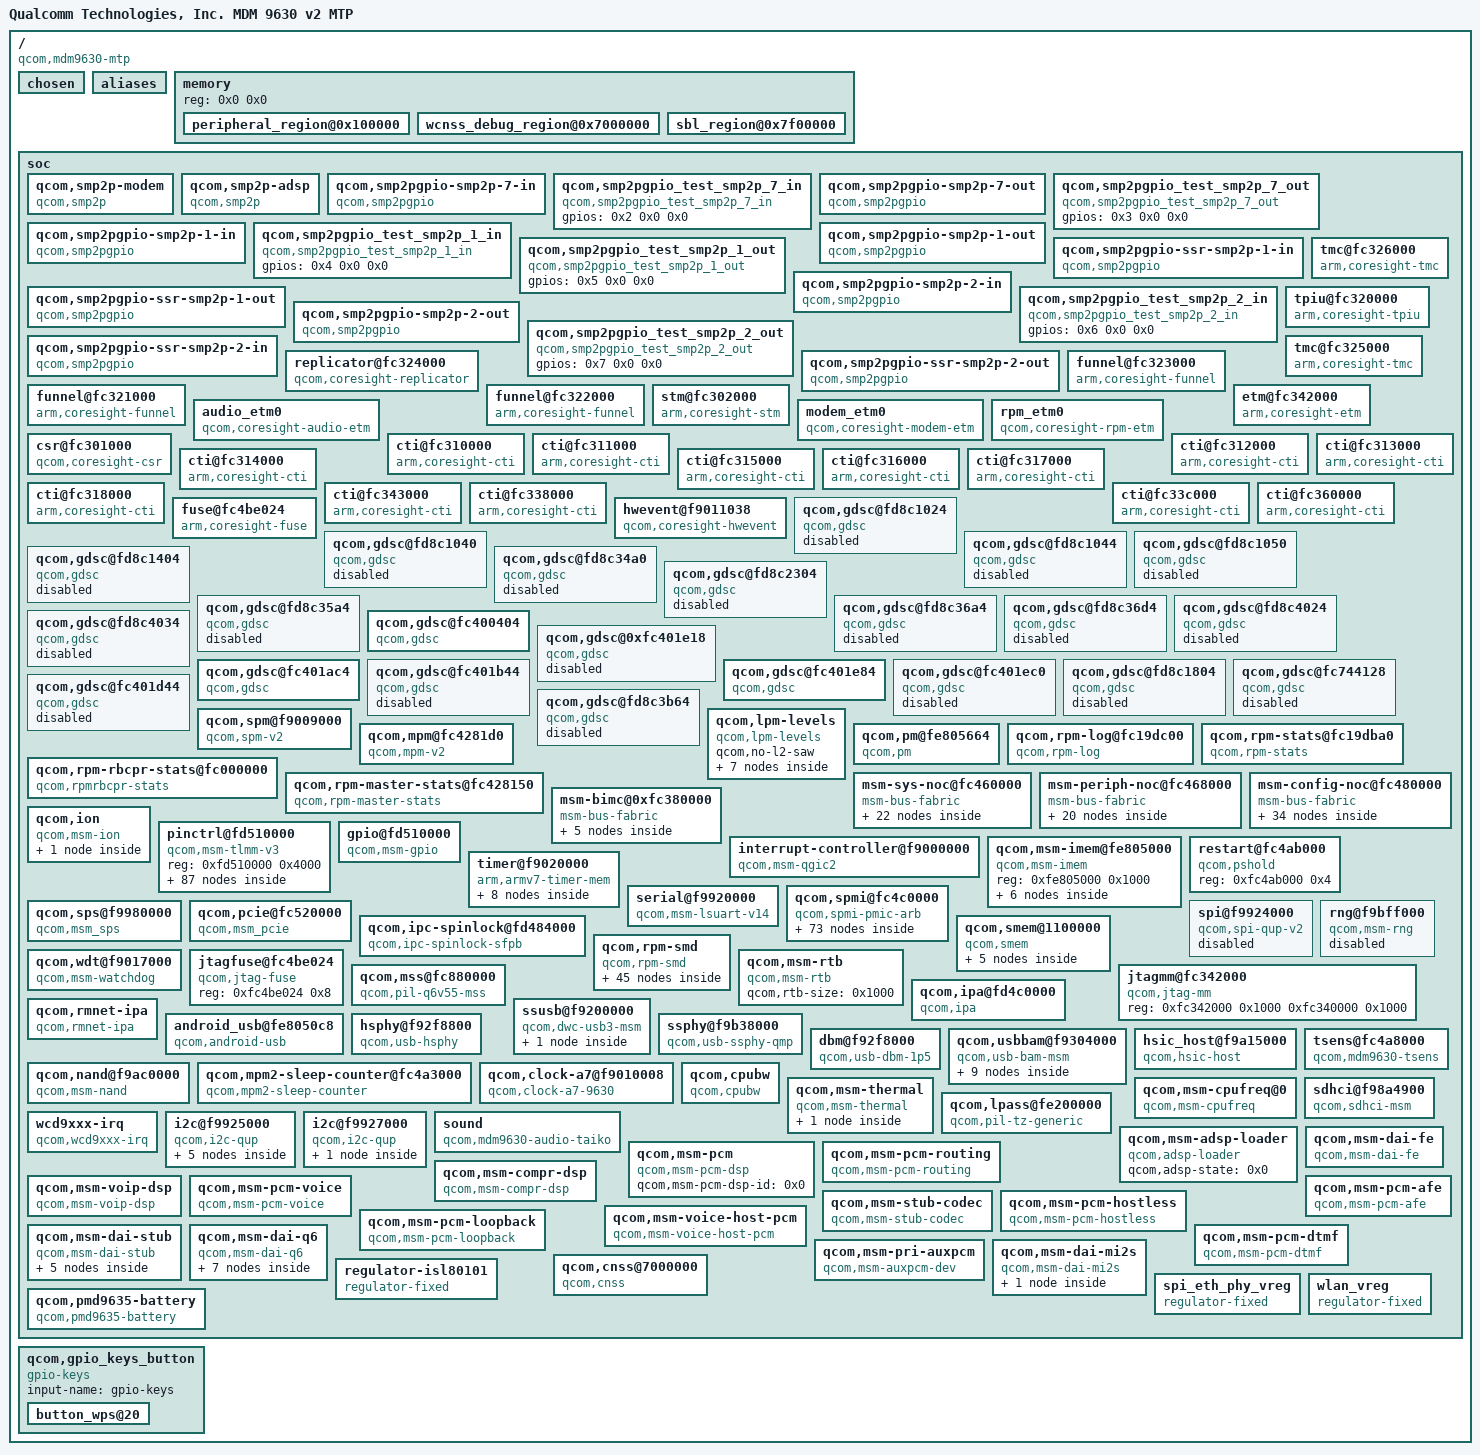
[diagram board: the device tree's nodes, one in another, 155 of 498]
/dts-v1/;

/memreserve/	0x0000000000000000 0x0000000000001000;
/ {
	#address-cells = <0x1>;
	#size-cells = <0x1>;
	model = "Qualcomm Technologies, Inc. MDM 9630 v2 MTP";
	compatible = "qcom,mdm9630-mtp", "qcom,mdm9630", "qcom,mtp";
	qcom,msm-id = <0x200bb 0x20000 0x200e3 0x20000 0x200e4 0x20000 0x200e5 0x20000 0x200e6 0x20000 0x200e7 0x20000>;
	interrupt-parent = <0x1>;
	qcom,board-id = <0x7 0x0>;

	chosen {
	};

	aliases {
		spi2 = "/soc/spi@f9924000";
		sdhc2 = "/soc/sdhci@f98a4900";
	};

	memory {
		#address-cells = <0x1>;
		#size-cells = <0x1>;
		device_type = "memory";
		reg = <0x0 0x0>;

		peripheral_region@0x100000 {
			linux,reserve-contiguous-region;
			linux,reserve-region;
			linux,remove-completely;
			reg = <0x1000000 0x5600000>;
			label = "peripheral_mem";
		};

		wcnss_debug_region@0x7000000 {
			linux,reserve-contiguous-region;
			linux,reserve-region;
			linux,remove-completely;
			reg = <0x7000000 0x100000>;
			label = "wcnss_debug_mem";
		};

		sbl_region@0x7f00000 {
			linux,reserve-contiguous-region;
			linux,reserve-region;
			linux,remove-completely;
			reg = <0x7f00000 0x100000>;
			label = "sbl_mem";
		};
	};

	soc {
		#address-cells = <0x1>;
		#size-cells = <0x1>;
		ranges;

		qcom,smp2p-modem {
			compatible = "qcom,smp2p";
			reg = <0xf9011008 0x4>;
			qcom,remote-pid = <0x1>;
			qcom,irq-bitmask = <0x4000>;
			interrupts = <0x0 0x1b 0x1>;
		};

		qcom,smp2p-adsp {
			compatible = "qcom,smp2p";
			reg = <0xf9011008 0x4>;
			qcom,remote-pid = <0x2>;
			qcom,irq-bitmask = <0x400>;
			interrupts = <0x0 0x9e 0x1>;
		};

		qcom,smp2pgpio-smp2p-7-in {
			compatible = "qcom,smp2pgpio";
			qcom,entry-name = "smp2p";
			qcom,remote-pid = <0x7>;
			qcom,is-inbound;
			gpio-controller;
			#gpio-cells = <0x2>;
			interrupt-controller;
			#interrupt-cells = <0x2>;
			linux,phandle = <0x2>;
			phandle = <0x2>;
		};

		qcom,smp2pgpio_test_smp2p_7_in {
			compatible = "qcom,smp2pgpio_test_smp2p_7_in";
			gpios = <0x2 0x0 0x0>;
		};

		qcom,smp2pgpio-smp2p-7-out {
			compatible = "qcom,smp2pgpio";
			qcom,entry-name = "smp2p";
			qcom,remote-pid = <0x7>;
			gpio-controller;
			#gpio-cells = <0x2>;
			interrupt-controller;
			#interrupt-cells = <0x2>;
			linux,phandle = <0x3>;
			phandle = <0x3>;
		};

		qcom,smp2pgpio_test_smp2p_7_out {
			compatible = "qcom,smp2pgpio_test_smp2p_7_out";
			gpios = <0x3 0x0 0x0>;
		};

		qcom,smp2pgpio-smp2p-1-in {
			compatible = "qcom,smp2pgpio";
			qcom,entry-name = "smp2p";
			qcom,remote-pid = <0x1>;
			qcom,is-inbound;
			gpio-controller;
			#gpio-cells = <0x2>;
			interrupt-controller;
			#interrupt-cells = <0x2>;
			linux,phandle = <0x4>;
			phandle = <0x4>;
		};

		qcom,smp2pgpio_test_smp2p_1_in {
			compatible = "qcom,smp2pgpio_test_smp2p_1_in";
			gpios = <0x4 0x0 0x0>;
		};

		qcom,smp2pgpio-smp2p-1-out {
			compatible = "qcom,smp2pgpio";
			qcom,entry-name = "smp2p";
			qcom,remote-pid = <0x1>;
			gpio-controller;
			#gpio-cells = <0x2>;
			interrupt-controller;
			#interrupt-cells = <0x2>;
			linux,phandle = <0x5>;
			phandle = <0x5>;
		};

		qcom,smp2pgpio_test_smp2p_1_out {
			compatible = "qcom,smp2pgpio_test_smp2p_1_out";
			gpios = <0x5 0x0 0x0>;
		};

		qcom,smp2pgpio-ssr-smp2p-1-in {
			compatible = "qcom,smp2pgpio";
			qcom,entry-name = "slave-kernel";
			qcom,remote-pid = <0x1>;
			qcom,is-inbound;
			gpio-controller;
			#gpio-cells = <0x2>;
			interrupt-controller;
			#interrupt-cells = <0x2>;
			linux,phandle = <0x1d>;
			phandle = <0x1d>;
		};

		qcom,smp2pgpio-ssr-smp2p-1-out {
			compatible = "qcom,smp2pgpio";
			qcom,entry-name = "master-kernel";
			qcom,remote-pid = <0x1>;
			gpio-controller;
			#gpio-cells = <0x2>;
			interrupt-controller;
			#interrupt-cells = <0x2>;
			linux,phandle = <0x1e>;
			phandle = <0x1e>;
		};

		qcom,smp2pgpio-smp2p-2-in {
			compatible = "qcom,smp2pgpio";
			qcom,entry-name = "smp2p";
			qcom,remote-pid = <0x2>;
			qcom,is-inbound;
			gpio-controller;
			#gpio-cells = <0x2>;
			interrupt-controller;
			#interrupt-cells = <0x2>;
			linux,phandle = <0x6>;
			phandle = <0x6>;
		};

		qcom,smp2pgpio_test_smp2p_2_in {
			compatible = "qcom,smp2pgpio_test_smp2p_2_in";
			gpios = <0x6 0x0 0x0>;
		};

		qcom,smp2pgpio-smp2p-2-out {
			compatible = "qcom,smp2pgpio";
			qcom,entry-name = "smp2p";
			qcom,remote-pid = <0x2>;
			gpio-controller;
			#gpio-cells = <0x2>;
			interrupt-controller;
			#interrupt-cells = <0x2>;
			linux,phandle = <0x7>;
			phandle = <0x7>;
		};

		qcom,smp2pgpio_test_smp2p_2_out {
			compatible = "qcom,smp2pgpio_test_smp2p_2_out";
			gpios = <0x7 0x0 0x0>;
		};

		qcom,smp2pgpio-ssr-smp2p-2-in {
			compatible = "qcom,smp2pgpio";
			qcom,entry-name = "slave-kernel";
			qcom,remote-pid = <0x2>;
			qcom,is-inbound;
			gpio-controller;
			#gpio-cells = <0x2>;
			interrupt-controller;
			#interrupt-cells = <0x2>;
			linux,phandle = <0x2a>;
			phandle = <0x2a>;
		};

		qcom,smp2pgpio-ssr-smp2p-2-out {
			compatible = "qcom,smp2pgpio";
			qcom,entry-name = "master-kernel";
			qcom,remote-pid = <0x2>;
			gpio-controller;
			#gpio-cells = <0x2>;
			interrupt-controller;
			#interrupt-cells = <0x2>;
			linux,phandle = <0x2b>;
			phandle = <0x2b>;
		};

		tmc@fc326000 {
			compatible = "arm,coresight-tmc";
			reg = <0xfc326000 0x1000 0xfc37c000 0x3000>;
			reg-names = "tmc-base", "bam-base";
			interrupts = <0x0 0xa6 0x0>;
			interrupt-names = "byte-cntr-irq";
			qcom,memory-size = <0x100000>;
			coresight-id = <0x0>;
			coresight-name = "coresight-tmc-etr";
			coresight-nr-inports = <0x1>;
			coresight-ctis = <0x8 0x9>;
			linux,phandle = <0xa>;
			phandle = <0xa>;
		};

		tpiu@fc320000 {
			compatible = "arm,coresight-tpiu";
			reg = <0xfc320000 0x1000>;
			reg-names = "tpiu-base";
			coresight-id = <0x1>;
			coresight-name = "coresight-tpiu";
			coresight-nr-inports = <0x1>;
			linux,phandle = <0xb>;
			phandle = <0xb>;
		};

		replicator@fc324000 {
			compatible = "qcom,coresight-replicator";
			reg = <0xfc324000 0x1000>;
			reg-names = "replicator-base";
			coresight-id = <0x2>;
			coresight-name = "coresight-replicator";
			coresight-nr-inports = <0x1>;
			coresight-outports = <0x0 0x1>;
			coresight-child-list = <0xa 0xb>;
			coresight-child-ports = <0x0 0x0>;
			linux,phandle = <0xc>;
			phandle = <0xc>;
		};

		tmc@fc325000 {
			compatible = "arm,coresight-tmc";
			reg = <0xfc325000 0x1000>;
			reg-names = "tmc-base";
			coresight-id = <0x3>;
			coresight-name = "coresight-tmc-etf";
			coresight-nr-inports = <0x1>;
			coresight-outports = <0x0>;
			coresight-child-list = <0xc>;
			coresight-child-ports = <0x0>;
			coresight-default-sink;
			coresight-ctis = <0x8 0x9>;
			linux,phandle = <0xd>;
			phandle = <0xd>;
		};

		funnel@fc323000 {
			compatible = "arm,coresight-funnel";
			reg = <0xfc323000 0x1000>;
			reg-names = "funnel-base";
			coresight-id = <0x4>;
			coresight-name = "coresight-funnel-merg";
			coresight-nr-inports = <0x2>;
			coresight-outports = <0x0>;
			coresight-child-list = <0xd>;
			coresight-child-ports = <0x0>;
			linux,phandle = <0xe>;
			phandle = <0xe>;
		};

		funnel@fc321000 {
			compatible = "arm,coresight-funnel";
			reg = <0xfc321000 0x1000>;
			reg-names = "funnel-base";
			coresight-id = <0x5>;
			coresight-name = "coresight-funnel-in0";
			coresight-nr-inports = <0x8>;
			coresight-outports = <0x0>;
			coresight-child-list = <0xe>;
			coresight-child-ports = <0x0>;
			linux,phandle = <0xf>;
			phandle = <0xf>;
		};

		funnel@fc322000 {
			compatible = "arm,coresight-funnel";
			reg = <0xfc322000 0x1000>;
			reg-names = "funnel-base";
			coresight-id = <0x6>;
			coresight-name = "coresight-funnel-in1";
			coresight-nr-inports = <0x8>;
			coresight-outports = <0x0>;
			coresight-child-list = <0xe>;
			coresight-child-ports = <0x1>;
			linux,phandle = <0x10>;
			phandle = <0x10>;
		};

		stm@fc302000 {
			compatible = "arm,coresight-stm";
			reg = <0xfc302000 0x1000 0xfa280000 0x180000>;
			reg-names = "stm-base", "stm-data-base";
			coresight-id = <0x7>;
			coresight-name = "coresight-stm";
			coresight-nr-inports = <0x0>;
			coresight-outports = <0x0>;
			coresight-child-list = <0xf>;
			coresight-child-ports = <0x7>;
		};

		etm@fc342000 {
			compatible = "arm,coresight-etm";
			reg = <0xfc342000 0x1000>;
			reg-names = "etm-base";
			coresight-id = <0x8>;
			coresight-name = "coresight-etm0";
			coresight-nr-inports = <0x0>;
			coresight-outports = <0x0>;
			coresight-child-list = <0x10>;
			coresight-child-ports = <0x2>;
			qcom,round-robin;
		};

		audio_etm0 {
			compatible = "qcom,coresight-audio-etm";
			coresight-id = <0x9>;
			coresight-name = "coresight-audio-etm0";
			coresight-nr-inports = <0x0>;
			coresight-outports = <0x0>;
			coresight-child-list = <0xf>;
			coresight-child-ports = <0x2>;
		};

		modem_etm0 {
			compatible = "qcom,coresight-modem-etm";
			coresight-id = <0xa>;
			coresight-name = "coresight-modem-etm0";
			coresight-nr-inports = <0x0>;
			coresight-outports = <0x0>;
			coresight-child-list = <0xf>;
			coresight-child-ports = <0x1>;
		};

		rpm_etm0 {
			compatible = "qcom,coresight-rpm-etm";
			coresight-id = <0xb>;
			coresight-name = "coresight-rpm-etm0";
			coresight-nr-inports = <0x0>;
			coresight-outports = <0x0>;
			coresight-child-list = <0xf>;
			coresight-child-ports = <0x0>;
		};

		csr@fc301000 {
			compatible = "qcom,coresight-csr";
			reg = <0xfc301000 0x1000>;
			reg-names = "csr-base";
			coresight-id = <0xc>;
			coresight-name = "coresight-csr";
			coresight-nr-inports = <0x0>;
			qcom,blk-size = <0x1>;
		};

		cti@fc310000 {
			compatible = "arm,coresight-cti";
			reg = <0xfc310000 0x1000>;
			reg-names = "cti-base";
			coresight-id = <0xd>;
			coresight-name = "coresight-cti0";
			coresight-nr-inports = <0x0>;
			linux,phandle = <0x8>;
			phandle = <0x8>;
		};

		cti@fc311000 {
			compatible = "arm,coresight-cti";
			reg = <0xfc311000 0x1000>;
			reg-names = "cti-base";
			coresight-id = <0xe>;
			coresight-name = "coresight-cti1";
			coresight-nr-inports = <0x0>;
		};

		cti@fc312000 {
			compatible = "arm,coresight-cti";
			reg = <0xfc312000 0x1000>;
			reg-names = "cti-base";
			coresight-id = <0xf>;
			coresight-name = "coresight-cti2";
			coresight-nr-inports = <0x0>;
		};

		cti@fc313000 {
			compatible = "arm,coresight-cti";
			reg = <0xfc313000 0x1000>;
			reg-names = "cti-base";
			coresight-id = <0x10>;
			coresight-name = "coresight-cti3";
			coresight-nr-inports = <0x0>;
		};

		cti@fc314000 {
			compatible = "arm,coresight-cti";
			reg = <0xfc314000 0x1000>;
			reg-names = "cti-base";
			coresight-id = <0x11>;
			coresight-name = "coresight-cti4";
			coresight-nr-inports = <0x0>;
		};

		cti@fc315000 {
			compatible = "arm,coresight-cti";
			reg = <0xfc315000 0x1000>;
			reg-names = "cti-base";
			coresight-id = <0x12>;
			coresight-name = "coresight-cti5";
			coresight-nr-inports = <0x0>;
		};

		cti@fc316000 {
			compatible = "arm,coresight-cti";
			reg = <0xfc316000 0x1000>;
			reg-names = "cti-base";
			coresight-id = <0x13>;
			coresight-name = "coresight-cti6";
			coresight-nr-inports = <0x0>;
		};

		cti@fc317000 {
			compatible = "arm,coresight-cti";
			reg = <0xfc317000 0x1000>;
			reg-names = "cti-base";
			coresight-id = <0x14>;
			coresight-name = "coresight-cti7";
			coresight-nr-inports = <0x0>;
		};

		cti@fc318000 {
			compatible = "arm,coresight-cti";
			reg = <0xfc318000 0x1000>;
			reg-names = "cti-base";
			coresight-id = <0x15>;
			coresight-name = "coresight-cti8";
			coresight-nr-inports = <0x0>;
			linux,phandle = <0x9>;
			phandle = <0x9>;
		};

		cti@fc343000 {
			compatible = "arm,coresight-cti";
			reg = <0xfc343000 0x1000>;
			reg-names = "cti-base";
			coresight-id = <0x16>;
			coresight-name = "coresight-cti-cpu0";
			coresight-nr-inports = <0x0>;
		};

		cti@fc338000 {
			compatible = "arm,coresight-cti";
			reg = <0xfc338000 0x1000>;
			reg-names = "cti-base";
			coresight-id = <0x17>;
			coresight-name = "coresight-cti-modem-cpu0";
			coresight-nr-inports = <0x0>;
		};

		cti@fc33c000 {
			compatible = "arm,coresight-cti";
			reg = <0xfc33c000 0x1000>;
			reg-names = "cti-base";
			coresight-id = <0x18>;
			coresight-name = "coresight-cti-audio-cpu0";
			coresight-nr-inports = <0x0>;
		};

		cti@fc360000 {
			compatible = "arm,coresight-cti";
			reg = <0xfc360000 0x1000>;
			reg-names = "cti-base";
			coresight-id = <0x19>;
			coresight-name = "coresight-cti-rpm-cpu0";
			coresight-nr-inports = <0x0>;
		};

		hwevent@f9011038 {
			compatible = "qcom,coresight-hwevent";
			reg = <0xf9011038 0x80 0xfd4ab160 0x80 0xfc401600 0x80>;
			reg-names = "apcs-mux", "ppss-mux", "gcc-mux";
			coresight-id = <0x1a>;
			coresight-name = "coresight-hwevent";
			coresight-nr-inports = <0x0>;
		};

		fuse@fc4be024 {
			compatible = "arm,coresight-fuse";
			reg = <0xfc4be024 0x8>;
			reg-names = "fuse-base";
			coresight-id = <0x1b>;
			coresight-name = "coresight-fuse";
			coresight-nr-inports = <0x0>;
		};

		qcom,gdsc@fd8c1024 {
			compatible = "qcom,gdsc";
			regulator-name = "gdsc_venus";
			reg = <0xfd8c1024 0x4>;
			status = "disabled";
		};

		qcom,gdsc@fd8c1040 {
			compatible = "qcom,gdsc";
			regulator-name = "gdsc_venus_core0";
			reg = <0xfd8c1040 0x4>;
			status = "disabled";
		};

		qcom,gdsc@fd8c1044 {
			compatible = "qcom,gdsc";
			regulator-name = "gdsc_venus_core1";
			reg = <0xfd8c1044 0x4>;
			status = "disabled";
		};

		qcom,gdsc@fd8c1050 {
			compatible = "qcom,gdsc";
			regulator-name = "gdsc_venus_core2";
			reg = <0xfd8c1050 0x4>;
			status = "disabled";
		};

		qcom,gdsc@fd8c1404 {
			compatible = "qcom,gdsc";
			regulator-name = "gdsc_vpu";
			reg = <0xfd8c1404 0x4>;
			status = "disabled";
		};

		qcom,gdsc@fd8c34a0 {
			compatible = "qcom,gdsc";
			regulator-name = "gdsc_camss_top";
			reg = <0xfd8c34a0 0x4>;
			status = "disabled";
		};

		qcom,gdsc@fd8c2304 {
			compatible = "qcom,gdsc";
			regulator-name = "gdsc_mdss";
			reg = <0xfd8c2304 0x4>;
			status = "disabled";
		};

		qcom,gdsc@fd8c35a4 {
			compatible = "qcom,gdsc";
			regulator-name = "gdsc_jpeg";
			reg = <0xfd8c35a4 0x4>;
			status = "disabled";
		};

		qcom,gdsc@fd8c36a4 {
			compatible = "qcom,gdsc";
			regulator-name = "gdsc_vfe";
			reg = <0xfd8c36a4 0x4>;
			status = "disabled";
		};

		qcom,gdsc@fd8c36d4 {
			compatible = "qcom,gdsc";
			regulator-name = "gdsc_cpp";
			reg = <0xfd8c36d4 0x4>;
			status = "disabled";
		};

		qcom,gdsc@fd8c4024 {
			compatible = "qcom,gdsc";
			regulator-name = "gdsc_oxili_gx";
			reg = <0xfd8c4024 0x4>;
			status = "disabled";
		};

		qcom,gdsc@fd8c4034 {
			compatible = "qcom,gdsc";
			regulator-name = "gdsc_oxili_cx";
			reg = <0xfd8c4034 0x4>;
			status = "disabled";
		};

		qcom,gdsc@fc400404 {
			compatible = "qcom,gdsc";
			regulator-name = "gdsc_usb_hsic";
			reg = <0xfc400404 0x4>;
			status = "ok";
			linux,phandle = <0x28>;
			phandle = <0x28>;
		};

		qcom,gdsc@0xfc401e18 {
			compatible = "qcom,gdsc";
			regulator-name = "gdsc_pcie";
			reg = <0xfc401e18 0x4>;
			status = "disabled";
		};

		qcom,gdsc@fc401ac4 {
			compatible = "qcom,gdsc";
			regulator-name = "gdsc_pcie_0";
			reg = <0xfc401e18 0x4>;
			status = "ok";
			linux,phandle = <0x16>;
			phandle = <0x16>;
		};

		qcom,gdsc@fc401b44 {
			compatible = "qcom,gdsc";
			regulator-name = "gdsc_pcie_1";
			reg = <0xfc401b44 0x4>;
			status = "disabled";
		};

		qcom,gdsc@fc401e84 {
			compatible = "qcom,gdsc";
			regulator-name = "gdsc_usb30";
			reg = <0xfc401b80 0x4>;
			status = "ok";
			linux,phandle = <0x21>;
			phandle = <0x21>;
		};

		qcom,gdsc@fc401ec0 {
			compatible = "qcom,gdsc";
			regulator-name = "gdsc_usb30_sec";
			reg = <0xfc401ec0 0x4>;
			status = "disabled";
		};

		qcom,gdsc@fd8c1804 {
			compatible = "qcom,gdsc";
			regulator-name = "gdsc_vcap";
			reg = <0xfd8c1804 0x4>;
			status = "disabled";
		};

		qcom,gdsc@fc744128 {
			compatible = "qcom,gdsc";
			regulator-name = "gdsc_bcss";
			reg = <0xfc744128 0x4>;
			status = "disabled";
		};

		qcom,gdsc@fc401d44 {
			compatible = "qcom,gdsc";
			regulator-name = "gdsc_ufs";
			reg = <0xfc401d44 0x4>;
			status = "disabled";
		};

		qcom,gdsc@fd8c3b64 {
			compatible = "qcom,gdsc";
			regulator-name = "gdsc_fd";
			reg = <0xfd8c3b64 0x4>;
			status = "disabled";
		};

		qcom,spm@f9009000 {
			compatible = "qcom,spm-v2";
			#address-cells = <0x1>;
			#size-cells = <0x1>;
			reg = <0xf9009000 0x1000>;
			qcom,core-id = <0x0>;
			qcom,saw2-ver-reg = <0xfd0>;
			qcom,saw2-cfg = <0x101>;
			#qcom,saw2-spm-dly = <0x0>;
			qcom,saw2-spm-dly = <0x3c102800>;
			qcom,saw2-spm-ctl = <0x1>;
			qcom,saw2-spm-cmd-wfi = <0x403040f>;
			qcom,saw2-spm-cmd-spc = <0x34044424 0x54035a24 0x44043a0f>;
			qcom,saw2-spm-cmd-pc = <0x34041424 0x54075a24 0x14043e0f>;
		};

		qcom,lpm-levels {
			compatible = "qcom,lpm-levels";
			qcom,no-l2-saw;
			#address-cells = <0x1>;
			#size-cells = <0x0>;

			qcom,cpu-modes {
				compatible = "qcom,cpu-modes";

				qcom,cpu-mode@0 {
					qcom,mode = "wfi";
					qcom,latency-us = <0x64>;
					qcom,ss-power = <0x1f40>;
					qcom,energy-overhead = <0x186a0>;
					qcom,time-overhead = <0x1>;
				};

				qcom,cpu-mode@1 {
					qcom,mode = "standalone_pc";
					qcom,latency-us = <0x7d0>;
					qcom,ss-power = <0x1388>;
					qcom,energy-overhead = <0x3950da0>;
					qcom,time-overhead = <0xbb8>;
				};

				qcom,cpu-mode@2 {
					qcom,mode = "pc";
					qcom,latency-us = <0x7530>;
					qcom,ss-power = <0x1388>;
					qcom,energy-overhead = <0x398de30>;
					qcom,time-overhead = <0x1c84>;
				};
			};

			qcom,system-modes {
				compatible = "qcom,system-modes";

				qcom,system-mode@0 {
					qcom,l2 = "l2_cache_pc";
					qcom,latency-us = <0x7d0>;
					qcom,ss-power = <0x1388>;
					qcom,energy-overhead = <0x3950da0>;
					qcom,time-overhead = <0xbb8>;
					qcom,min-cpu-mode = "standalone_pc";
					qcom,sync-mode;
				};

				qcom,system-mode@1 {
					qcom,l2 = "l2_cache_pc";
					qcom,latency-us = <0x7530>;
					qcom,ss-power = <0x1388>;
					qcom,energy-overhead = <0x398de30>;
					qcom,time-overhead = <0x1c84>;
					qcom,min-cpu-mode = "pc";
					qcom,send-rpm-sleep-set;
					qcom,sync-mode;
				};
			};
		};

		qcom,mpm@fc4281d0 {
			compatible = "qcom,mpm-v2";
			reg = <0xfc4281d0 0x1000 0xf9011008 0x4>;
			reg-names = "vmpm", "ipc";
			interrupts = <0x0 0xab 0x1>;
			clock-names = "xo";
			qcom,ipc-bit-offset = <0x1>;
			qcom,gic-parent = <0x1>;
			qcom,gic-map = <0x2 0xd8 0x2f 0xac 0x29 0xb4 0x3e 0xde 0xff 0x12 0xff 0x26 0xff 0x38 0xff 0x39 0xff 0x3a 0xff 0x3b 0xff 0x3c 0xff 0x49 0xff 0x7e 0x31 0xa5 0x36 0xd4 0xff 0xad 0xff 0xae 0xff 0xaf 0xff 0xb0 0xff 0xb1 0xff 0xb2 0xff 0xb3 0xff 0xbc 0xff 0xbd 0xff 0xbe 0xff 0xbf 0xff 0xc0 0xff 0xc1 0xff 0xc2 0xff 0xc3 0xff 0xc4 0xff 0xc5 0xff 0xc6 0xff 0xc8 0xff 0xc9 0xff 0xca 0xff 0xcb 0xff 0xcc 0xff 0xcd 0xff 0xce 0xff 0xcf 0xff 0xf0 0xff 0x10e>;
			qcom,gpio-parent = <0x11>;
			qcom,gpio-map = <0x3 0x50 0x4 0x0 0x5 0x1 0x6 0x2 0x7 0x3 0x8 0x4 0x9 0x5 0xa 0x6 0xb 0x7 0xc 0x8 0xd 0x9 0xe 0xa 0xf 0xb 0x10 0xc 0x11 0xd 0x12 0xe 0x13 0xf 0x14 0x10 0x15 0x11 0x16 0x12 0x17 0x13 0x18 0x14 0x19 0x15 0x1a 0x18 0x1b 0x19 0x1c 0x33 0x1d 0x51 0x1e 0x3e 0x1f 0x3f 0x20 0x40 0x21 0x41 0x22 0x42 0x23 0x43 0x24 0x2b 0x25 0x32 0x26 0x35 0x27 0x36 0x28 0x37 0x2a 0x38 0x2b 0x52 0x2f 0x4d 0x32 0x53 0x33 0x54 0x34 0x55 0x35 0x3a 0x37 0x3b 0x39 0x44 0x3b 0x46>;
		};

		qcom,pm@fe805664 {
			compatible = "qcom,pm";
			reg = <0xfe805664 0x40>;
			qcom,use-sync-timer;
			qcom,synced-clocks;
		};

		qcom,rpm-log@fc19dc00 {
			compatible = "qcom,rpm-log";
			reg = <0xfc19dc00 0x4000>;
			qcom,rpm-addr-phys = <0xfc000000>;
			qcom,offset-version = <0x4>;
			qcom,offset-page-buffer-addr = <0x24>;
			qcom,offset-log-len = <0x28>;
			qcom,offset-log-len-mask = <0x2c>;
			qcom,offset-page-indices = <0x38>;
		};

		qcom,rpm-stats@fc19dba0 {
			compatible = "qcom,rpm-stats";
			reg = <0xfc19dba0 0x1000>;
			reg-names = "phys_addr_base";
			qcom,sleep-stats-version = <0x2>;
		};

		qcom,rpm-rbcpr-stats@fc000000 {
			compatible = "qcom,rpmrbcpr-stats";
			reg = <0xfc000000 0x1a0000>;
			qcom,start-offset = <0x190010>;
		};

		qcom,rpm-master-stats@fc428150 {
			compatible = "qcom,rpm-master-stats";
			reg = <0xfc428150 0x3200>;
			qcom,masters = "APSS", "MPSS", "LPSS";
			qcom,master-stats-version = <0x2>;
			qcom,master-offset = <0xa00>;
		};

		msm-sys-noc@fc460000 {
			compatible = "msm-bus-fabric";
			reg = <0xfc460000 0x4000>;
			cell-id = <0x400>;
			label = "msm_sys_noc";
			qcom,fabclk-dual = "bus_clk";
			qcom,fabclk-active = "bus_a_clk";
			qcom,ntieredslaves = <0x0>;
			qcom,qos-freq = <0x12c0>;
			qcom,hw-sel = "NoC";
			qcom,rpm-en;
			qcom,nfab = <0x4>;

			mas-lpass-ahb {
				cell-id = <0x34>;
				label = "mas-lpass-ahb";
				qcom,masterp = <0x0>;
				qcom,tier = <0x2>;
				qcom,qport = <0x0>;
				qcom,mas-hw-id = <0x12>;
				qcom,mode = "Fixed";
				qcom,prio-rd = <0x2>;
				qcom,prio-wr = <0x2>;
			};

			mas-qdss-bam {
				cell-id = <0x35>;
				label = "mas-qdss-bam";
				qcom,masterp = <0x1>;
				qcom,tier = <0x2>;
				qcom,mode = "Fixed";
				qcom,qport = <0x1>;
				qcom,mas-hw-id = <0x13>;
			};

			mas-snoc-cfg {
				cell-id = <0x36>;
				label = "mas-snoc-cfg";
				qcom,masterp = <0x2>;
				qcom,tier = <0x2>;
				qcom,mas-hw-id = <0x14>;
			};

			fab-bimc {
				cell-id = <0x0>;
				label = "fab-bimc";
				qcom,gateway;
				qcom,slavep = <0x2>;
				qcom,masterp = <0x3>;
				qcom,buswidth = <0x8>;
				qcom,mas-hw-id = <0x15>;
				qcom,slv-hw-id = <0x18>;
			};

			fab-cnoc {
				cell-id = <0x1400>;
				label = "fab-cnoc";
				qcom,gateway;
				qcom,slavep = <0x3>;
				qcom,masterp = <0x4>;
				qcom,buswidth = <0x8>;
				qcom,mas-hw-id = <0x16>;
				qcom,slv-hw-id = <0x19>;
			};

			fab-pnoc {
				cell-id = <0x1000>;
				label = "fab-pnoc";
				qcom,gateway;
				qcom,slavep = <0x5>;
				qcom,masterp = <0xb>;
				qcom,buswidth = <0x8>;
				qcom,qport = <0x8>;
				qcom,mas-hw-id = <0x1d>;
				qcom,slv-hw-id = <0x1c>;
				qcom,mode = "Fixed";
				qcom,prio-rd = <0x2>;
				qcom,prio-wr = <0x2>;
			};

			fab-ovnoc {
				cell-id = <0x1800>;
				label = "fab-ovnoc";
				qcom,gateway;
				qcom,buswidth = <0x8>;
				qcom,mas-hw-id = <0x35>;
				qcom,slv-hw-id = <0x4d>;
			};

			mas-crypto-core0 {
				cell-id = <0x37>;
				label = "mas-crypto-core0";
				qcom,masterp = <0x5>;
				qcom,tier = <0x2>;
				qcom,mode = "Fixed";
				qcom,qport = <0x2>;
				qcom,mas-hw-id = <0x17>;
				qcom,hw-sel = "NoC";
			};

			mas-lpass-proc {
				cell-id = <0xb>;
				label = "mas-lpass-proc";
				qcom,masterp = <0x7>;
				qcom,tier = <0x2>;
				qcom,qport = <0x4>;
				qcom,mas-hw-id = <0x19>;
				qcom,mode = "Fixed";
				qcom,prio-rd = <0x2>;
				qcom,prio-wr = <0x2>;
			};

			mas-mss {
				cell-id = <0x26>;
				label = "mas-mss";
				qcom,masterp = <0x8>;
				qcom,tier = <0x2>;
				qcom,mas-hw-id = <0x1a>;
			};

			mas-mss-nav {
				cell-id = <0x39>;
				label = "mas-mss-nav";
				qcom,masterp = <0x9>;
				qcom,tier = <0x2>;
				qcom,mas-hw-id = <0x1b>;
			};

			mas-ipa {
				cell-id = <0x5a>;
				label = "mas-ipa";
				qcom,masterp = <0x6>;
				qcom,tier = <0x2>;
				qcom,mode = "Fixed";
				qcom,qport = <0x3>;
				qcom,mas-hw-id = <0x3b>;
				qcom,hw-sel = "NoC";
				qcom,iface-clk-node = "msm_ipa";
			};

			mas-qdss-etr {
				cell-id = <0x3c>;
				label = "mas-qdss-etr";
				qcom,masterp = <0xc>;
				qcom,tier = <0x2>;
				qcom,qport = <0xa>;
				qcom,mode = "Fixed";
				qcom,mas-hw-id = <0x1f>;
			};

			mas-usb3 {
				cell-id = <0x3d>;
				label = "mas-usb3";
				qcom,masterp = <0xa>;
				qcom,tier = <0x2>;
				qcom,qport = <0x7>;
				qcom,mode = "Fixed";
				qcom,mas-hw-id = <0x20>;
				qcom,hw-sel = "NoC";
				qcom,iface-clk-node = "msm_usb3";
			};

			mas-pcie-0 {
				cell-id = <0x2d>;
				label = "mas-pcie-0";
				qcom,masterp = <0xd>;
				qcom,tier = <0x2>;
				qcom,mode = "Fixed";
				qcom,mas-hw-id = <0x41>;
				qcom,hw-sel = "NoC";
			};

			slv-ampss {
				cell-id = <0x208>;
				label = "slv-ampss";
				qcom,slavep = <0x0>;
				qcom,tier = <0x2>;
				qcom,buswidth = <0x8>;
				qcom,slv-hw-id = <0x14>;
			};

			slv-lpass {
				cell-id = <0x20a>;
				label = "slv-lpass";
				qcom,slavep = <0x1>;
				qcom,tier = <0x2>;
				qcom,buswidth = <0x8>;
				qcom,slv-hw-id = <0x15>;
			};

			slv-ocimem {
				cell-id = <0x249>;
				label = "slv-ocimem";
				qcom,slavep = <0x4>;
				qcom,tier = <0x2>;
				qcom,buswidth = <0x8>;
				qcom,slv-hw-id = <0x1a>;
			};

			slv-service-snoc {
				cell-id = <0x24b>;
				label = "slv-service-snoc";
				qcom,slavep = <0x6>;
				qcom,tier = <0x2>;
				qcom,buswidth = <0x8>;
				qcom,slv-hw-id = <0x1d>;
			};

			slv-qdss-stm {
				cell-id = <0x24c>;
				label = "slv-qdss-stm";
				qcom,slavep = <0x7>;
				qcom,tier = <0x2>;
				qcom,buswidth = <0x8>;
				qcom,slv-hw-id = <0x1e>;
			};

			slv-usb3 {
				cell-id = <0x247>;
				label = "slv-usb3";
				qcom,slavep = <0x9>;
				qcom,tier = <0x2>;
				qcom,buswidth = <0x8>;
				qcom,slv-hw-id = <0x16>;
			};

			slv-pcie-0 {
				cell-id = <0x28d>;
				label = "slv-pcie-0";
				qcom,slavep = <0x8>;
				qcom,tier = <0x2>;
				qcom,buswidth = <0x8>;
				qcom,slv-hw-id = <0x55>;
			};
		};

		msm-periph-noc@fc468000 {
			compatible = "msm-bus-fabric";
			reg = <0xfc468000 0x4000>;
			cell-id = <0x1000>;
			label = "msm_periph_noc";
			qcom,fabclk-dual = "bus_clk";
			qcom,fabclk-active = "bus_a_clk";
			qcom,ntieredslaves = <0x0>;
			qcom,hw-sel = "NoC";
			qcom,nfab = <0x4>;
			qcom,rpm-en;

			mas-pnoc-cfg {
				cell-id = <0x58>;
				label = "mas-pnoc-cfg";
				qcom,masterp = <0x7>;
				qcom,tier = <0x2>;
				qcom,buswidth = <0x8>;
				qcom,mas-hw-id = <0x2b>;
			};

			mas-qpic-cfg {
				cell-id = <0x5b>;
				label = "mas-qpic";
				qcom,masterp = <0x1>;
				qcom,tier = <0x2>;
				qcom,buswidth = <0x8>;
				qcom,mas-hw-id = <0x3a>;
			};

			mas-sdcc-2 {
				cell-id = <0x51>;
				label = "mas-sdcc-2";
				qcom,masterp = <0x2>;
				qcom,tier = <0x2>;
				qcom,buswidth = <0x8>;
				qcom,mas-hw-id = <0x23>;
			};

			mas-bam-dma {
				cell-id = <0x53>;
				label = "mas-bam-dma";
				qcom,masterp = <0x3>;
				qcom,tier = <0x2>;
				qcom,buswidth = <0x8>;
				qcom,mas-hw-id = <0x26>;
			};

			mas-usb-hsic {
				cell-id = <0x55>;
				label = "mas-usb-hsic";
				qcom,masterp = <0x4>;
				qcom,tier = <0x2>;
				qcom,buswidth = <0x8>;
				qcom,mas-hw-id = <0x28>;
			};

			mas-blsp-1 {
				cell-id = <0x56>;
				label = "mas-blsp-1";
				qcom,masterp = <0x5>;
				qcom,tier = <0x2>;
				qcom,buswidth = <0x8>;
				qcom,mas-hw-id = <0x29>;
			};

			mas-usb-hs {
				cell-id = <0x57>;
				label = "mas-usb-hs";
				qcom,masterp = <0x6>;
				qcom,tier = <0x2>;
				qcom,buswidth = <0x8>;
				qcom,mas-hw-id = <0x2a>;
			};

			fab-snoc {
				cell-id = <0x400>;
				label = "fab-snoc";
				qcom,gateway;
				qcom,slavep = <0xc>;
				qcom,masterp = <0x8>;
				qcom,tier = <0x2>;
				qcom,buswidth = <0x8>;
				qcom,slv-hw-id = <0x2d>;
				qcom,mas-hw-id = <0x2c>;
			};

			slv-qpic {
				cell-id = <0x288>;
				label = "slv-qpic";
				qcom,slavep = <0x2>;
				qcom,tier = <0x2>;
				qcom,buswidth = <0x8>;
				qcom,slv-hw-id = <0x51>;
			};

			slv-sdcc-2 {
				cell-id = <0x260>;
				label = "slv-sdcc-2";
				qcom,slavep = <0x1>;
				qcom,tier = <0x2>;
				qcom,buswidth = <0x8>;
				qcom,slv-hw-id = <0x21>;
			};

			slv-bam-dma {
				cell-id = <0x262>;
				label = "slv-bam-dma";
				qcom,slavep = <0x2>;
				qcom,tier = <0x2>;
				qcom,buswidth = <0x8>;
				qcom,slv-hw-id = <0x24>;
			};

			slv-usb-hsic {
				cell-id = <0x264>;
				label = "slv-usb-hsic";
				qcom,slavep = <0x3>;
				qcom,tier = <0x2>;
				qcom,buswidth = <0x8>;
				qcom,slv-hw-id = <0x26>;
			};

			slv-blsp-1 {
				cell-id = <0x265>;
				label = "slv-blsp-1";
				qcom,slavep = <0x5>;
				qcom,tier = <0x2>;
				qcom,buswidth = <0x8>;
				qcom,slv-hw-id = <0x27>;
			};

			slv-usb-hs {
				cell-id = <0x266>;
				label = "slv-usb-hs";
				qcom,slavep = <0x5>;
				qcom,tier = <0x2>;
				qcom,buswidth = <0x8>;
				qcom,slv-hw-id = <0x28>;
			};

			slv-pdm {
				cell-id = <0x267>;
				label = "slv-pdm";
				qcom,slavep = <0x6>;
				qcom,tier = <0x2>;
				qcom,buswidth = <0x8>;
				qcom,slv-hw-id = <0x29>;
			};

			slv-periph-apu-cfg {
				cell-id = <0x268>;
				label = "slv-periph-apu-cfg";
				qcom,slavep = <0x7>;
				qcom,tier = <0x2>;
				qcom,buswidth = <0x8>;
				qcom,slv-hw-id = <0x2a>;
			};

			slv-pnoc-mpu-cfg {
				cell-id = <0x269>;
				label = "slv-pnoc-mpu-cfg";
				qcom,slavep = <0x8>;
				qcom,tier = <0x2>;
				qcom,buswidth = <0x8>;
				qcom,slv-hw-id = <0x2b>;
			};

			slv-usb-phy {
				cell-id = <0x28d>;
				label = "slv-usb-phy";
				qcom,slavep = <0x9>;
				qcom,tier = <0x2>;
				qcom,buswidth = <0x8>;
				qcom,slv-hw-id = <0x5f>;
			};

			slv-prng {
				cell-id = <0x26a>;
				label = "slv-prng";
				qcom,slavep = <0xa>;
				qcom,tier = <0x2>;
				qcom,buswidth = <0x8>;
				qcom,slv-hw-id = <0x2c>;
			};

			slv-service-pnoc {
				cell-id = <0x26b>;
				label = "slv-service-pnoc";
				qcom,slavep = <0xc>;
				qcom,tier = <0x2>;
				qcom,buswidth = <0x8>;
				qcom,slv-hw-id = <0x2e>;
			};
		};

		msm-config-noc@fc480000 {
			compatible = "msm-bus-fabric";
			reg = <0xfc480000 0x4000>;
			cell-id = <0x1400>;
			label = "msm_config_noc";
			qcom,fabclk-dual = "bus_clk";
			qcom,fabclk-active = "bus_a_clk";
			qcom,ntieredslaves = <0x0>;
			qcom,hw-sel = "NoC";
			qcom,nfab = <0x4>;
			qcom,rpm-en;

			mas-rpm-inst {
				cell-id = <0x48>;
				label = "mas-rpm-inst";
				qcom,masterp = <0x0>;
				qcom,tier = <0x2>;
				qcom,buswidth = <0x8>;
				qcom,mas-hw-id = <0x2d>;
			};

			mas-rpm-data {
				cell-id = <0x49>;
				label = "mas-rpm-data";
				qcom,masterp = <0x1>;
				qcom,tier = <0x2>;
				qcom,buswidth = <0x8>;
				qcom,mas-hw-id = <0x2e>;
			};

			mas-rpm-sys {
				cell-id = <0x4a>;
				label = "mas-rpm-sys";
				qcom,masterp = <0x2>;
				qcom,tier = <0x2>;
				qcom,buswidth = <0x8>;
				qcom,mas-hw-id = <0x2f>;
			};

			mas-dehr {
				cell-id = <0x4b>;
				label = "mas-dehr";
				qcom,masterp = <0x3>;
				qcom,tier = <0x2>;
				qcom,buswidth = <0x8>;
				qcom,mas-hw-id = <0x30>;
			};

			mas-qdss-dap {
				cell-id = <0x4c>;
				label = "mas-qdss-dap";
				qcom,masterp = <0x4>;
				qcom,tier = <0x2>;
				qcom,buswidth = <0x8>;
				qcom,mas-hw-id = <0x31>;
			};

			mas-spdm {
				cell-id = <0x24>;
				label = "mas-spdm";
				qcom,masterp = <0x5>;
				qcom,tier = <0x2>;
				qcom,buswidth = <0x8>;
				qcom,mas-hw-id = <0x32>;
			};

			mas-tic {
				cell-id = <0x4d>;
				label = "mas-tic";
				qcom,masterp = <0x6>;
				qcom,tier = <0x2>;
				qcom,buswidth = <0x8>;
				qcom,mas-hw-id = <0x33>;
			};

			fab-snoc {
				cell-id = <0x400>;
				label = "fab-snoc";
				qcom,gateway;
				qcom,slavep = <0x1a>;
				qcom,masterp = <0x7>;
				qcom,tier = <0x2>;
				qcom,buswidth = <0x8>;
				qcom,mas-hw-id = <0x34>;
				qcom,slv-hw-id = <0x4b>;
			};

			slv-clk-ctl {
				cell-id = <0x26c>;
				label = "slv-clk-ctl";
				qcom,slavep = <0x0>;
				qcom,tier = <0x2>;
				qcom,buswidth = <0x8>;
				qcom,slv-hw-id = <0x2f>;
			};

			slv-cnoc-mss {
				cell-id = <0x26d>;
				label = "slv-cnoc-mss";
				qcom,slavep = <0x1>;
				qcom,tier = <0x2>;
				qcom,buswidth = <0x8>;
				qcom,slv-hw-id = <0x30>;
			};

			slv-security {
				cell-id = <0x26e>;
				label = "slv-security";
				qcom,slavep = <0x2>;
				qcom,tier = <0x2>;
				qcom,buswidth = <0x8>;
				qcom,slv-hw-id = <0x31>;
			};

			slv-tcsr {
				cell-id = <0x26f>;
				label = "slv-tcsr";
				qcom,slavep = <0x3>;
				qcom,tier = <0x2>;
				qcom,buswidth = <0x8>;
				qcom,slv-hw-id = <0x32>;
			};

			slv-tlmm {
				cell-id = <0x270>;
				label = "slv-tlmm";
				qcom,slavep = <0x4>;
				qcom,tier = <0x2>;
				qcom,buswidth = <0x8>;
				qcom,slv-hw-id = <0x33>;
			};

			slv-crypto-0-cfg {
				cell-id = <0x271>;
				label = "slv-crypto-0-cfg";
				qcom,slavep = <0x5>;
				qcom,tier = <0x2>;
				qcom,buswidth = <0x8>;
				qcom,slv-hw-id = <0x34>;
			};

			slv-imem-cfg {
				cell-id = <0x273>;
				label = "slv-imem-cfg";
				qcom,slavep = <0x6>;
				qcom,tier = <0x2>;
				qcom,buswidth = <0x8>;
				qcom,slv-hw-id = <0x36>;
			};

			slv-message-ram {
				cell-id = <0x274>;
				label = "slv-message-ram";
				qcom,slavep = <0x7>;
				qcom,tier = <0x2>;
				qcom,buswidth = <0x8>;
				qcom,slv-hw-id = <0x37>;
			};

			slv-bimc-cfg {
				cell-id = <0x275>;
				label = "slv-bimc-cfg";
				qcom,slavep = <0x8>;
				qcom,tier = <0x2>;
				qcom,buswidth = <0x8>;
				qcom,slv-hw-id = <0x38>;
			};

			slv-boot-rom {
				cell-id = <0x276>;
				label = "slv-boot-rom";
				qcom,slavep = <0x9>;
				qcom,tier = <0x2>;
				qcom,buswidth = <0x8>;
				qcom,slv-hw-id = <0x39>;
			};

			slv-pmic-arb {
				cell-id = <0x278>;
				label = "slv-pmic-arb";
				qcom,slavep = <0xa>;
				qcom,tier = <0x2>;
				qcom,buswidth = <0x8>;
				qcom,slv-hw-id = <0x3b>;
			};

			slv-spdm-wrapper {
				cell-id = <0x279>;
				label = "slv-spdm-wrapper";
				qcom,slavep = <0xb>;
				qcom,tier = <0x2>;
				qcom,buswidth = <0x8>;
				qcom,slv-hw-id = <0x3c>;
			};

			slv-dehr-cfg {
				cell-id = <0x27a>;
				label = "slv-dehr-cfg";
				qcom,slavep = <0xc>;
				qcom,tier = <0x2>;
				qcom,buswidth = <0x8>;
				qcom,slv-hw-id = <0x3d>;
			};

			slv-mpm {
				cell-id = <0x218>;
				label = "slv-mpm";
				qcom,slavep = <0xd>;
				qcom,tier = <0x2>;
				qcom,buswidth = <0x8>;
				qcom,slv-hw-id = <0x3e>;
			};

			slv-qdss-cfg {
				cell-id = <0x27b>;
				label = "slv-qdss-cfg";
				qcom,slavep = <0xe>;
				qcom,tier = <0x2>;
				qcom,buswidth = <0x8>;
				qcom,slv-hw-id = <0x3f>;
			};

			slv-rbcpr-cx-cfg {
				cell-id = <0x28a>;
				label = "slv-rbcpr-cx-cfg";
				qcom,slavep = <0xf>;
				qcom,tier = <0x2>;
				qcom,buswidth = <0x8>;
				qcom,slv-hw-id = <0x40>;
			};

			slv-rbcpr-mx-cfg {
				cell-id = <0x28b>;
				label = "slv-rbcpr-mx-cfg";
				qcom,slavep = <0x10>;
				qcom,tier = <0x2>;
				qcom,buswidth = <0x8>;
				qcom,slv-hw-id = <0x60>;
			};

			slv-rbcpr-qdss-apu-cfg {
				cell-id = <0x27d>;
				label = "slv-rbcpr-qdss-apu-cfg";
				qcom,slavep = <0x11>;
				qcom,tier = <0x2>;
				qcom,buswidth = <0x8>;
				qcom,slv-hw-id = <0x41>;
			};

			slv-pnoc-cfg {
				cell-id = <0x281>;
				label = "slv-pnoc-cfg";
				qcom,slavep = <0x14>;
				qcom,tier = <0x2>;
				qcom,buswidth = <0x8>;
				qcom,slv-hw-id = <0x45>;
			};

			slv-snoc-pcie-cfg {
				cell-id = <0x28c>;
				label = "slv-snoc-pcie-cfg";
				qcom,slavep = <0x12>;
				qcom,tier = <0x2>;
				qcom,buswidth = <0x8>;
				qcom,slv-hw-id = <0x43>;
			};

			slv-snoc-mpu-cfg {
				cell-id = <0x27e>;
				label = "slv-snoc-mpu-cfg";
				qcom,slavep = <0x13>;
				qcom,tier = <0x2>;
				qcom,buswidth = <0x8>;
				qcom,slv-hw-id = <0x43>;
			};

			slv-snoc-cfg {
				cell-id = <0x282>;
				label = "slv-snoc-cfg";
				qcom,slavep = <0x15>;
				qcom,tier = <0x2>;
				qcom,buswidth = <0x8>;
				qcom,slv-hw-id = <0x46>;
			};

			slv-phy-apu-cfg {
				cell-id = <0x284>;
				label = "slv-phy-apu-cfg";
				qcom,slavep = <0x16>;
				qcom,tier = <0x2>;
				qcom,buswidth = <0x8>;
				qcom,slv-hw-id = <0x48>;
			};

			slv-ebi1-phy-cfg {
				cell-id = <0x285>;
				label = "slv-ebi1-phy-cfg";
				qcom,slavep = <0x17>;
				qcom,tier = <0x2>;
				qcom,buswidth = <0x8>;
				qcom,slv-hw-id = <0x49>;
			};

			slv-rpm {
				cell-id = <0x216>;
				label = "slv-rpm";
				qcom,slavep = <0x18>;
				qcom,tier = <0x2>;
				qcom,buswidth = <0x8>;
				qcom,slv-hw-id = <0x4a>;
			};

			slv-service-cnoc {
				cell-id = <0x286>;
				label = "slv-service-cnoc";
				qcom,slavep = <0x1a>;
				qcom,tier = <0x2>;
				qcom,buswidth = <0x8>;
				qcom,slv-hw-id = <0x4c>;
			};
		};

		msm-bimc@0xfc380000 {
			compatible = "msm-bus-fabric";
			reg = <0xfc380000 0x6a000>;
			cell-id = <0x0>;
			label = "msm_bimc";
			qcom,fabclk-dual = "mem_clk";
			qcom,fabclk-active = "mem_a_clk";
			qcom,ntieredslaves = <0x0>;
			qcom,qos-freq = <0x12c0>;
			qcom,hw-sel = "BIMC";
			qcom,nfab = <0x4>;
			qcom,rpm-en;

			mas-ampss-m0 {
				cell-id = <0x1>;
				label = "mas-ampss-m0";
				qcom,masterp = <0x0>;
				qcom,tier = <0x2>;
				qcom,hw-sel = "BIMC";
				qcom,mode = "Fixed";
				qcom,qport = <0x0>;
				qcom,ws = <0x2710>;
				qcom,mas-hw-id = <0x0>;
				qcom,prio-rd = <0x0>;
				qcom,prio-wr = <0x0>;
			};

			mas-mss-proc {
				cell-id = <0x41>;
				label = "mas-mss-proc";
				qcom,masterp = <0x1>;
				qcom,tier = <0x2>;
				qcom,hw-sel = "RPM";
				qcom,mas-hw-id = <0x1>;
			};

			fab-snoc {
				cell-id = <0x400>;
				label = "fab-snoc";
				qcom,gateway;
				qcom,slavep = <0x1>;
				qcom,masterp = <0x2>;
				qcom,qport = <0x4>;
				qcom,buswidth = <0x8>;
				qcom,ws = <0x2710>;
				qcom,mas-hw-id = <0x3>;
				qcom,slv-hw-id = <0x2>;
				qcom,mode = "Bypass";
				qcom,hw-sel = "RPM";
			};

			slv-ebi-ch0 {
				cell-id = <0x200>;
				label = "slv-ebi-ch0";
				qcom,slavep = <0x0>;
				qcom,tier = <0x2>;
				qcom,buswidth = <0x8>;
				qcom,slv-hw-id = <0x0>;
				qcom,mode = "Bypass";
			};

			slv-ampss-l2 {
				cell-id = <0x202>;
				label = "slv-ampss-l2";
				qcom,slavep = <0x1>;
				qcom,tier = <0x2>;
				qcom,buswidth = <0x8>;
				qcom,slv-hw-id = <0x1>;
			};
		};

		qcom,ion {
			compatible = "qcom,msm-ion";
			#address-cells = <0x1>;
			#size-cells = <0x0>;

			qcom,ion-heap@25 {
				reg = <0x19>;
				qcom,ion-heap-type = "SYSTEM";
			};
		};

		pinctrl@fd510000 {
			compatible = "qcom,msm-tlmm-v3";
			reg = <0xfd510000 0x4000>;

			gp {
				qcom,pin-type-gp;
				qcom,num-pins = <0x5a>;
				#qcom,pin-cells = <0x1>;
				linux,phandle = <0x12>;
				phandle = <0x12>;

				msm_gpio {
					compatible = "qcom,msm-tlmmv3-gp-intc";
					gpio-controller;
					#gpio-cells = <0x2>;
					#interrupt-cells = <0x2>;
					num_irqs = <0x5a>;
				};
			};

			sdhc2_cd_pin {
				qcom,pins = <0x12 0x32>;
				qcom,num-grp-pins = <0x1>;
				qcom,pin-func = <0x0>;
				label = "cd-gpio";

				cd_on {
					drive-strength = <0x2>;
					bias-pull-up;
					linux,phandle = <0x31>;
					phandle = <0x31>;
				};

				cd_off {
					drive-strength = <0x2>;
					bias-disable;
					linux,phandle = <0x35>;
					phandle = <0x35>;
				};
			};

			sdc {
				qcom,pin-type-sdc;
				qcom,num-pins = <0x7>;
				#qcom,pin-cells = <0x1>;
				linux,phandle = <0x13>;
				phandle = <0x13>;
			};

			pmx_sdc2_clk {
				qcom,pins = <0x13 0x4>;
				qcom,num-grp-pins = <0x1>;
				label = "sdc2-clk";

				clk_on {
					bias-disable;
					drive-strength = <0xa>;
					linux,phandle = <0x2e>;
					phandle = <0x2e>;
				};

				clk_off {
					bias-disable;
					drive-strength = <0x2>;
					linux,phandle = <0x32>;
					phandle = <0x32>;
				};
			};

			pmx_sdc2_cmd {
				qcom,pins = <0x13 0x5>;
				qcom,num-grp-pins = <0x1>;
				label = "sdc2-cmd";

				cmd_on {
					bias-pull-up;
					drive-strength = <0xa>;
					linux,phandle = <0x2f>;
					phandle = <0x2f>;
				};

				cmd_off {
					bias-pull-up;
					drive-strength = <0x2>;
					linux,phandle = <0x33>;
					phandle = <0x33>;
				};
			};

			pmx_sdc2_data {
				qcom,pins = <0x13 0x6>;
				qcom,num-grp-pins = <0x1>;
				label = "sdc2-data";

				data_on {
					bias-pull-up;
					drive-strength = <0xa>;
					linux,phandle = <0x30>;
					phandle = <0x30>;
				};

				data_off {
					bias-pull-up;
					drive-strength = <0x2>;
					linux,phandle = <0x34>;
					phandle = <0x34>;
				};
			};

			tpiu_seta_1 {
				qcom,pins = <0x12 0x4>;
				qcom,num-grp-pins = <0x1>;
				qcom,pin-func = <0x8>;
				label = "tpiu-seta-1";

				seta {
					drive-strength = <0x10>;
					bias-disable;
				};
			};

			tpiu_seta_2 {
				qcom,pins = <0x12 0x5>;
				qcom,num-grp-pins = <0x1>;
				qcom,pin-func = <0x8>;
				label = "tpiu-seta-2";

				seta {
					drive-strength = <0x10>;
					bias-disable;
				};
			};

			tpiu_seta_3 {
				qcom,pins = <0x12 0x6>;
				qcom,num-grp-pins = <0x1>;
				qcom,pin-func = <0xa>;
				label = "tpiu-seta-3";

				seta {
					drive-strength = <0x10>;
					bias-disable;
				};
			};

			tpiu_seta_4 {
				qcom,pins = <0x12 0x7>;
				qcom,num-grp-pins = <0x1>;
				qcom,pin-func = <0xa>;
				label = "tpiu-seta-4";

				seta {
					drive-strength = <0x10>;
					bias-disable;
				};
			};

			tpiu_seta_5 {
				qcom,pins = <0x12 0x8>;
				qcom,num-grp-pins = <0x1>;
				qcom,pin-func = <0x5>;
				label = "tpiu-seta-5";

				seta {
					drive-strength = <0x10>;
					bias-disable;
				};
			};

			tpiu_seta_6 {
				qcom,pins = <0x12 0x9>;
				qcom,num-grp-pins = <0x1>;
				qcom,pin-func = <0x5>;
				label = "tpiu-seta-6";

				seta {
					drive-strength = <0x10>;
					bias-disable;
				};
			};

			tpiu_seta_7 {
				qcom,pins = <0x12 0xc>;
				qcom,num-grp-pins = <0x1>;
				qcom,pin-func = <0x8>;
				label = "tpiu-seta-7";

				seta {
					drive-strength = <0x10>;
					bias-disable;
				};
			};

			tpiu_seta_8 {
				qcom,pins = <0x12 0xd>;
				qcom,num-grp-pins = <0x1>;
				qcom,pin-func = <0x8>;
				label = "tpiu-seta-8";

				seta {
					drive-strength = <0x10>;
					bias-disable;
				};
			};

			tpiu_seta_9 {
				qcom,pins = <0x12 0xe>;
				qcom,num-grp-pins = <0x1>;
				qcom,pin-func = <0xa>;
				label = "tpiu-seta-9";

				seta {
					drive-strength = <0x10>;
					bias-disable;
				};
			};

			tpiu_seta_10 {
				qcom,pins = <0x12 0xf>;
				qcom,num-grp-pins = <0x1>;
				qcom,pin-func = <0xa>;
				label = "tpiu-seta-10";

				seta {
					drive-strength = <0x10>;
					bias-disable;
				};
			};

			tpiu_seta_11 {
				qcom,pins = <0x12 0x10>;
				qcom,num-grp-pins = <0x1>;
				qcom,pin-func = <0x9>;
				label = "tpiu-seta-11";

				seta {
					drive-strength = <0x10>;
					bias-disable;
				};
			};

			tpiu_seta_12 {
				qcom,pins = <0x12 0x11>;
				qcom,num-grp-pins = <0x1>;
				qcom,pin-func = <0x8>;
				label = "tpiu-seta-12";

				seta {
					drive-strength = <0x10>;
					bias-disable;
				};
			};

			tpiu_seta_13 {
				qcom,pins = <0x12 0x12>;
				qcom,num-grp-pins = <0x1>;
				qcom,pin-func = <0xa>;
				label = "tpiu-seta-13";

				seta {
					drive-strength = <0x10>;
					bias-disable;
				};
			};

			tpiu_seta_14 {
				qcom,pins = <0x12 0x13>;
				qcom,num-grp-pins = <0x1>;
				qcom,pin-func = <0xa>;
				label = "tpiu-seta-14";

				seta {
					drive-strength = <0x10>;
					bias-disable;
				};
			};

			tpiu_seta_15 {
				qcom,pins = <0x12 0x19>;
				qcom,num-grp-pins = <0x1>;
				qcom,pin-func = <0x4>;
				label = "tpiu-seta-15";

				seta {
					drive-strength = <0x10>;
					bias-disable;
				};
			};

			tpiu_seta_16 {
				qcom,pins = <0x12 0x33>;
				qcom,num-grp-pins = <0x1>;
				qcom,pin-func = <0x1>;
				label = "tpiu-seta-16";

				seta {
					drive-strength = <0x10>;
					bias-disable;
				};
			};

			tpiu_seta_17 {
				qcom,pins = <0x12 0x43>;
				qcom,num-grp-pins = <0x1>;
				qcom,pin-func = <0xb>;
				label = "tpiu-seta-17";

				seta {
					drive-strength = <0x10>;
					bias-disable;
				};
			};

			tpiu_seta_18 {
				qcom,pins = <0x12 0x45>;
				qcom,num-grp-pins = <0x1>;
				qcom,pin-func = <0x9>;
				label = "tpiu-seta-18";

				seta {
					drive-strength = <0x10>;
					bias-disable;
				};
			};

			tpiu_setb_1 {
				qcom,pins = <0x12 0x10>;
				qcom,num-grp-pins = <0x1>;
				qcom,pin-func = <0xa>;
				label = "tpiu-setb-1";

				setb {
					drive-strength = <0x10>;
					bias-disable;
				};
			};

			tpiu_setb_2 {
				qcom,pins = <0x12 0x11>;
				qcom,num-grp-pins = <0x1>;
				qcom,pin-func = <0x9>;
				label = "tpiu-setb-2";

				setb {
					drive-strength = <0x10>;
					bias-disable;
				};
			};

			tpiu_setb_3 {
				qcom,pins = <0x12 0x12>;
				qcom,num-grp-pins = <0x1>;
				qcom,pin-func = <0xb>;
				label = "tpiu-setb-3";

				setb {
					drive-strength = <0x10>;
					bias-disable;
				};
			};

			tpiu_setb_4 {
				qcom,pins = <0x12 0x13>;
				qcom,num-grp-pins = <0x1>;
				qcom,pin-func = <0xb>;
				label = "tpiu-setb-4";

				setb {
					drive-strength = <0x10>;
					bias-disable;
				};
			};

			tpiu_setb_5 {
				qcom,pins = <0x12 0x19>;
				qcom,num-grp-pins = <0x1>;
				qcom,pin-func = <0x5>;
				label = "tpiu-setb-5";

				setb {
					drive-strength = <0x10>;
					bias-disable;
				};
			};

			tpiu_setb_6 {
				qcom,pins = <0x12 0x21>;
				qcom,num-grp-pins = <0x1>;
				qcom,pin-func = <0x2>;
				label = "tpiu-setb-6";

				setb {
					drive-strength = <0x10>;
					bias-disable;
				};
			};

			tpiu_setb_7 {
				qcom,pins = <0x12 0x22>;
				qcom,num-grp-pins = <0x1>;
				qcom,pin-func = <0x2>;
				label = "tpiu-setb-7";

				setb {
					drive-strength = <0x10>;
					bias-disable;
				};
			};

			tpiu_setb_8 {
				qcom,pins = <0x12 0x24>;
				qcom,num-grp-pins = <0x1>;
				qcom,pin-func = <0x3>;
				label = "tpiu-setb-8";

				setb {
					drive-strength = <0x10>;
					bias-disable;
				};
			};

			tpiu_setb_9 {
				qcom,pins = <0x12 0x26>;
				qcom,num-grp-pins = <0x1>;
				qcom,pin-func = <0x2>;
				label = "tpiu-setb-9";

				setb {
					drive-strength = <0x10>;
					bias-disable;
				};
			};

			tpiu_setb_10 {
				qcom,pins = <0x12 0x27>;
				qcom,num-grp-pins = <0x1>;
				qcom,pin-func = <0x2>;
				label = "tpiu-setb-10";

				setb {
					drive-strength = <0x10>;
					bias-disable;
				};
			};

			tpiu_setb_11 {
				qcom,pins = <0x12 0x32>;
				qcom,num-grp-pins = <0x1>;
				qcom,pin-func = <0x2>;
				label = "tpiu-setb-11";

				setb {
					drive-strength = <0x10>;
					bias-disable;
				};
			};

			tpiu_setb_12 {
				qcom,pins = <0x12 0x33>;
				qcom,num-grp-pins = <0x1>;
				qcom,pin-func = <0x2>;
				label = "tpiu-setb-12";

				setb {
					drive-strength = <0x10>;
					bias-disable;
				};
			};

			tpiu_setb_13 {
				qcom,pins = <0x12 0x34>;
				qcom,num-grp-pins = <0x1>;
				qcom,pin-func = <0x3>;
				label = "tpiu-setb-13";

				setb {
					drive-strength = <0x10>;
					bias-disable;
				};
			};

			tpiu_setb_14 {
				qcom,pins = <0x12 0x35>;
				qcom,num-grp-pins = <0x1>;
				qcom,pin-func = <0x3>;
				label = "tpiu-setb-14";

				setb {
					drive-strength = <0x10>;
					bias-disable;
				};
			};

			tpiu_setb_15 {
				qcom,pins = <0x12 0x3e>;
				qcom,num-grp-pins = <0x1>;
				qcom,pin-func = <0x5>;
				label = "tpiu-setb-15";

				setb {
					drive-strength = <0x10>;
					bias-disable;
				};
			};

			tpiu_setb_16 {
				qcom,pins = <0x12 0x3f>;
				qcom,num-grp-pins = <0x1>;
				qcom,pin-func = <0x6>;
				label = "tpiu-setb-16";

				setb {
					drive-strength = <0x10>;
					bias-disable;
				};
			};

			tpiu_setb_17 {
				qcom,pins = <0x12 0x43>;
				qcom,num-grp-pins = <0x1>;
				qcom,pin-func = <0xc>;
				label = "tpiu-setb-17";

				setb {
					drive-strength = <0x10>;
					bias-disable;
				};
			};

			tpiu_setb_18 {
				qcom,pins = <0x12 0x46>;
				qcom,num-grp-pins = <0x1>;
				qcom,pin-func = <0x4>;
				label = "tpiu-setb-18";

				setb {
					drive-strength = <0x10>;
					bias-disable;
				};
			};
		};

		interrupt-controller@f9000000 {
			compatible = "qcom,msm-qgic2";
			interrupt-controller;
			#interrupt-cells = <0x3>;
			reg = <0xf9000000 0x1000 0xf9002000 0x1000>;
			linux,phandle = <0x1>;
			phandle = <0x1>;
		};

		gpio@fd510000 {
			compatible = "qcom,msm-gpio";
			gpio-controller;
			#gpio-cells = <0x2>;
			interrupt-controller;
			#interrupt-cells = <0x2>;
			reg = <0xfd510000 0x4000>;
			ngpio = <0x5a>;
			interrupts = <0x0 0xd0 0x0>;
			qcom,direct-connect-irqs = <0x8>;
			linux,phandle = <0x11>;
			phandle = <0x11>;
		};

		qcom,msm-imem@fe805000 {
			compatible = "qcom,msm-imem";
			reg = <0xfe805000 0x1000>;
			ranges = <0x0 0xfe805000 0x1000>;
			#address-cells = <0x1>;
			#size-cells = <0x1>;

			download_mode@0 {
				compatible = "qcom,msm-imem-download_mode";
				reg = <0x0 0x8>;
			};

			mem_dump_table@14 {
				compatible = "qcom,msm-imem-mem_dump_table";
				reg = <0x14 0x4>;
			};

			restart_reason@65c {
				compatible = "qcom,msm-imem-restart_reason";
				reg = <0x65c 0x4>;
			};

			boot_stats@6b0 {
				compatible = "qcom,msm-imem-boot_stats";
				reg = <0x6b0 0x20>;
			};

			pil@94c {
				compatible = "qcom,msm-imem-pil";
				reg = <0x94c 0xc8>;
			};

			emergency_download_mode@fe0 {
				compatible = "qcom,msm-imem-emergency_download_mode";
				reg = <0xfe0 0xc>;
			};
		};

		restart@fc4ab000 {
			compatible = "qcom,pshold";
			reg = <0xfc4ab000 0x4>;
		};

		timer@f9020000 {
			#address-cells = <0x1>;
			#size-cells = <0x1>;
			ranges;
			compatible = "arm,armv7-timer-mem";
			reg = <0xf9020000 0x1000>;
			clock-frequency = <0x124f800>;

			frame@f9021000 {
				frame-number = <0x0>;
				interrupts = <0x0 0x7 0x4 0x0 0x6 0x4>;
				reg = <0xf9021000 0x1000 0xf9022000 0x1000>;
			};

			frame@f9023000 {
				frame-number = <0x1>;
				interrupts = <0x0 0x8 0x4>;
				reg = <0xf9023000 0x1000>;
				status = "disabled";
			};

			frame@f9024000 {
				frame-number = <0x2>;
				interrupts = <0x0 0x9 0x4>;
				reg = <0xf9024000 0x1000>;
				status = "disabled";
			};

			frame@f9025000 {
				frame-number = <0x3>;
				interrupts = <0x0 0xa 0x4>;
				reg = <0xf9025000 0x1000>;
				status = "disabled";
			};

			frame@f9026000 {
				frame-number = <0x4>;
				interrupts = <0x0 0xb 0x4>;
				reg = <0xf9026000 0x1000>;
				status = "disabled";
			};

			frame@f9027000 {
				frame-number = <0x5>;
				interrupts = <0x0 0xc 0x4>;
				reg = <0xf9027000 0x1000>;
				status = "disabled";
			};

			frame@f9028000 {
				frame-number = <0x6>;
				interrupts = <0x0 0xd 0x4>;
				reg = <0xf9028000 0x1000>;
				status = "disabled";
			};

			frame@f9029000 {
				frame-number = <0x7>;
				interrupts = <0x0 0xe 0x4>;
				reg = <0xf9029000 0x1000>;
				status = "disabled";
			};
		};

		serial@f9920000 {
			compatible = "qcom,msm-lsuart-v14";
			reg = <0xf9920000 0x1000>;
			interrupts = <0x0 0x6e 0x0>;
			status = "ok";
		};

		qcom,spmi@fc4c0000 {
			compatible = "qcom,spmi-pmic-arb";
			reg = <0xfc4cf000 0x1000 0xfc4cb000 0x1000 0xfc4ca000 0x1000>;
			reg-names = "core", "intr", "cnfg";
			interrupts = <0x0 0xbe 0x0>;
			qcom,pmic-arb-channel = <0x0>;
			qcom,pmic-arb-ee = <0x0>;
			#interrupt-cells = <0x3>;
			interrupt-controller;
			#address-cells = <0x1>;
			#size-cells = <0x0>;
			cell-index = <0x0>;
			linux,phandle = <0x20>;
			phandle = <0x20>;

			qcom,pmd9635@0 {
				spmi-slave-container;
				reg = <0x0>;
				#address-cells = <0x1>;
				#size-cells = <0x1>;

				qcom,revid@100 {
					compatible = "qcom,qpnp-revid";
					reg = <0x100 0x100>;
				};

				qcom,power-on@800 {
					compatible = "qcom,qpnp-power-on";
					reg = <0x800 0x100>;
					interrupts = <0x0 0x8 0x2>;
					interrupt-names = "cblpwr";
					qcom,pon-dbc-delay = <0x3d09>;
					qcom,system-reset;

					qcom,pon_1 {
						qcom,pon-type = <0x2>;
						qcom,pull-up = <0x1>;
						linux,code = <0x74>;
					};
				};

				gpios {
					spmi-dev-container;
					compatible = "qcom,qpnp-pin";
					gpio-controller;
					#gpio-cells = <0x2>;
					#address-cells = <0x1>;
					#size-cells = <0x1>;
					label = "pmd9635-gpio";

					gpio@c000 {
						reg = <0xc000 0x100>;
						qcom,pin-num = <0x1>;
						status = "disabled";
					};

					gpio@c100 {
						reg = <0xc100 0x100>;
						qcom,pin-num = <0x2>;
						status = "disabled";
					};

					gpio@c200 {
						reg = <0xc200 0x100>;
						qcom,pin-num = <0x3>;
					};

					gpio@c300 {
						reg = <0xc300 0x100>;
						qcom,pin-num = <0x4>;
					};

					gpio@c400 {
						reg = <0xc400 0x100>;
						qcom,pin-num = <0x5>;
						status = "disabled";
					};

					gpio@c500 {
						reg = <0xc500 0x100>;
						qcom,pin-num = <0x6>;
						status = "disabled";
					};
				};

				mpps {
					spmi-dev-container;
					compatible = "qcom,qpnp-pin";
					gpio-controller;
					#gpio-cells = <0x2>;
					#address-cells = <0x1>;
					#size-cells = <0x1>;
					label = "pmd9635-mpp";

					mpp@a000 {
						reg = <0xa000 0x100>;
						qcom,pin-num = <0x1>;
					};

					mpp@a100 {
						reg = <0xa100 0x100>;
						qcom,pin-num = <0x2>;
						qcom,mode = <0x4>;
						qcom,ain-route = <0x1>;
						qcom,master-en = <0x1>;
						qcom,src-sel = <0x0>;
						qcom,invert = <0x1>;
					};

					mpp@a200 {
						reg = <0xa200 0x100>;
						qcom,pin-num = <0x3>;
					};

					mpp@a300 {
						reg = <0xa300 0x100>;
						qcom,pin-num = <0x4>;
						qcom,mode = <0x4>;
						qcom,ain-route = <0x3>;
						qcom,master-en = <0x1>;
						qcom,src-sel = <0x0>;
						qcom,invert = <0x1>;
					};

					mpp@a400 {
						reg = <0xa400 0x100>;
						qcom,pin-num = <0x5>;
						status = "disabled";
					};

					mpp@a500 {
						reg = <0xa500 0x100>;
						qcom,pin-num = <0x6>;
						qcom,mode = <0x4>;
						qcom,ain-route = <0x1>;
						qcom,master-en = <0x1>;
						qcom,src-sel = <0x0>;
						qcom,invert = <0x1>;
					};
				};

				qcom,pmd9635_rtc {
					spmi-dev-container;
					compatible = "qcom,qpnp-rtc";
					#address-cells = <0x1>;
					#size-cells = <0x1>;
					qcom,qpnp-rtc-write = <0x0>;
					qcom,qpnp-rtc-alarm-pwrup = <0x0>;

					qcom,pmd9635_rtc_rw@6000 {
						reg = <0x6000 0x100>;
					};

					qcom,pmd9635_rtc_alarm@6100 {
						reg = <0x6100 0x100>;
						interrupts = <0x0 0x61 0x1>;
					};
				};

				vadc@3100 {
					compatible = "qcom,qpnp-vadc";
					reg = <0x3100 0x100>;
					#address-cells = <0x1>;
					#size-cells = <0x0>;
					interrupts = <0x0 0x31 0x0>;
					interrupt-names = "eoc-int-en-set";
					qcom,adc-bit-resolution = <0xf>;
					qcom,adc-vdd-reference = <0x708>;
					qcom,vadc-poll-eoc;
					linux,phandle = <0x14>;
					phandle = <0x14>;

					chan@8 {
						label = "die_temp";
						reg = <0x8>;
						qcom,decimation = <0x0>;
						qcom,pre-div-channel-scaling = <0x0>;
						qcom,calibration-type = "absolute";
						qcom,scale-function = <0x3>;
						qcom,hw-settle-time = <0x0>;
						qcom,fast-avg-setup = <0x0>;
					};

					chan@9 {
						label = "ref_625mv";
						reg = <0x9>;
						qcom,decimation = <0x0>;
						qcom,pre-div-channel-scaling = <0x0>;
						qcom,calibration-type = "absolute";
						qcom,scale-function = <0x0>;
						qcom,hw-settle-time = <0x0>;
						qcom,fast-avg-setup = <0x0>;
					};

					chan@a {
						label = "ref_1250v";
						reg = <0xa>;
						qcom,decimation = <0x0>;
						qcom,pre-div-channel-scaling = <0x0>;
						qcom,calibration-type = "absolute";
						qcom,scale-function = <0x0>;
						qcom,hw-settle-time = <0x0>;
						qcom,fast-avg-setup = <0x0>;
					};

					chan@31 {
						label = "batt_id_therm";
						reg = <0x31>;
						qcom,decimation = <0x0>;
						qcom,pre-div-channel-scaling = <0x0>;
						qcom,calibration-type = "ratiometric";
						qcom,scale-function = <0x0>;
						qcom,hw-settle-time = <0x2>;
						qcom,fast-avg-setup = <0x0>;
					};

					chan@33 {
						label = "pa_therm0";
						reg = <0x33>;
						qcom,decimation = <0x0>;
						qcom,pre-div-channel-scaling = <0x0>;
						qcom,calibration-type = "ratiometric";
						qcom,scale-function = <0x2>;
						qcom,hw-settle-time = <0x2>;
						qcom,fast-avg-setup = <0x0>;
					};

					chan@34 {
						label = "pa_therm1";
						reg = <0x34>;
						qcom,decimation = <0x0>;
						qcom,pre-div-channel-scaling = <0x0>;
						qcom,calibration-type = "ratiometric";
						qcom,scale-function = <0x2>;
						qcom,hw-settle-time = <0x2>;
						qcom,fast-avg-setup = <0x0>;
					};

					chan@32 {
						label = "xo_therm";
						reg = <0x32>;
						qcom,decimation = <0x0>;
						qcom,pre-div-channel-scaling = <0x0>;
						qcom,calibration-type = "ratiometric";
						qcom,scale-function = <0x4>;
						qcom,hw-settle-time = <0x2>;
						qcom,fast-avg-setup = <0x0>;
					};

					chan@3c {
						label = "xo_therm_amux";
						reg = <0x3c>;
						qcom,decimation = <0x0>;
						qcom,pre-div-channel-scaling = <0x0>;
						qcom,calibration-type = "ratiometric";
						qcom,scale-function = <0x4>;
						qcom,hw-settle-time = <0x2>;
						qcom,fast-avg-setup = <0x0>;
					};

					chan@13 {
						label = "case_therm";
						reg = <0x13>;
						qcom,decimation = <0x0>;
						qcom,pre-div-channel-scaling = <0x0>;
						qcom,calibration-type = "ratiometric";
						qcom,scale-function = <0x2>;
						qcom,hw-settle-time = <0x2>;
						qcom,fast-avg-setup = <0x0>;
					};

					chan@15 {
						label = "vbat";
						reg = <0x15>;
						qcom,decimation = <0x0>;
						qcom,pre-div-channel-scaling = <0x1>;
						qcom,calibration-type = "ratiometric";
						qcom,scale-function = <0x0>;
						qcom,hw-settle-time = <0x0>;
						qcom,fast-avg-setup = <0x0>;
					};

					chan@11 {
						label = "tbat";
						reg = <0x11>;
						qcom,decimation = <0x0>;
						qcom,pre-div-channel-scaling = <0x0>;
						qcom,calibration-type = "ratiometric";
						qcom,scale-function = <0x0>;
						qcom,hw-settle-time = <0x0>;
						qcom,fast-avg-setup = <0x0>;
					};
				};

				vadc@3400 {
					compatible = "qcom,qpnp-adc-tm";
					reg = <0x3400 0x100>;
					#address-cells = <0x1>;
					#size-cells = <0x0>;
					interrupts = <0x0 0x34 0x0 0x0 0x34 0x3 0x0 0x34 0x4>;
					interrupt-names = "eoc-int-en-set", "high-thr-en-set", "low-thr-en-set";
					qcom,adc-bit-resolution = <0xf>;
					qcom,adc-vdd-reference = <0x708>;
					qcom,adc_tm-vadc = <0x14>;

					chan@33 {
						label = "pa_therm0";
						reg = <0x33>;
						qcom,decimation = <0x0>;
						qcom,pre-div-channel-scaling = <0x0>;
						qcom,calibration-type = "ratiometric";
						qcom,scale-function = <0x2>;
						qcom,hw-settle-time = <0x2>;
						qcom,fast-avg-setup = <0x0>;
						qcom,btm-channel-number = <0x48>;
						qcom,thermal-node;
					};

					chan@34 {
						label = "pa_therm1";
						reg = <0x34>;
						qcom,decimation = <0x0>;
						qcom,pre-div-channel-scaling = <0x0>;
						qcom,calibration-type = "ratiometric";
						qcom,scale-function = <0x2>;
						qcom,hw-settle-time = <0x2>;
						qcom,fast-avg-setup = <0x0>;
						qcom,btm-channel-number = <0x68>;
						qcom,thermal-node;
					};
				};
			};

			qcom,pmd9635@1 {
				spmi-slave-container;
				reg = <0x1>;
				#address-cells = <0x1>;
				#size-cells = <0x1>;

				regulator@1400 {
					compatible = "qcom,qpnp-regulator";
					regulator-name = "9635_s1";
					spmi-dev-container;
					#address-cells = <0x1>;
					#size-cells = <0x1>;
					reg = <0x1400 0x300>;
					status = "disabled";

					qcom,ctl@1400 {
						reg = <0x1400 0x100>;
					};

					qcom,ps@1500 {
						reg = <0x1500 0x100>;
					};

					qcom,freq@1600 {
						reg = <0x1600 0x100>;
					};
				};

				regulator@1700 {
					compatible = "qcom,qpnp-regulator";
					regulator-name = "9635_s2";
					spmi-dev-container;
					#address-cells = <0x1>;
					#size-cells = <0x1>;
					reg = <0x1700 0x300>;
					status = "disabled";

					qcom,ctl@1700 {
						reg = <0x1700 0x100>;
					};

					qcom,ps@1800 {
						reg = <0x1800 0x100>;
					};

					qcom,freq@1900 {
						reg = <0x1900 0x100>;
					};
				};

				regulator@1a00 {
					compatible = "qcom,qpnp-regulator";
					regulator-name = "9635_s3";
					spmi-dev-container;
					#address-cells = <0x1>;
					#size-cells = <0x1>;
					reg = <0x1a00 0x300>;
					status = "disabled";

					qcom,ctl@x1a00 {
						reg = <0x1a00 0x100>;
					};

					qcom,ps@1b00 {
						reg = <0x1b00 0x100>;
					};

					qcom,freq@1c00 {
						reg = <0x1c00 0x100>;
					};
				};

				regulator@2000 {
					compatible = "qcom,qpnp-regulator";
					regulator-name = "9635_s4";
					spmi-dev-container;
					#address-cells = <0x1>;
					#size-cells = <0x1>;
					reg = <0x2000 0x300>;
					status = "disabled";

					qcom,ctl@2000 {
						reg = <0x2000 0x100>;
					};

					qcom,ps@2100 {
						reg = <0x2100 0x100>;
					};

					qcom,freq@2200 {
						reg = <0x2200 0x100>;
					};
				};

				regulator@2300 {
					compatible = "qcom,qpnp-regulator";
					regulator-name = "9635_s5";
					spmi-dev-container;
					#address-cells = <0x1>;
					#size-cells = <0x1>;
					reg = <0x2300 0x300>;
					status = "disabled";

					qcom,ctl@2300 {
						reg = <0x2300 0x100>;
					};

					qcom,ps@2400 {
						reg = <0x2400 0x100>;
					};

					qcom,freq@2500 {
						reg = <0x2500 0x100>;
					};
				};

				regulator@4000 {
					compatible = "qcom,qpnp-regulator";
					regulator-name = "9635_l1";
					reg = <0x4000 0x100>;
					status = "disabled";
				};

				regulator@4100 {
					compatible = "qcom,qpnp-regulator";
					regulator-name = "9635_l2";
					reg = <0x4100 0x100>;
					status = "disabled";
				};

				regulator@4200 {
					compatible = "qcom,qpnp-regulator";
					regulator-name = "9635_l3";
					reg = <0x4200 0x100>;
					status = "disabled";
				};

				regulator@4300 {
					compatible = "qcom,qpnp-regulator";
					regulator-name = "9635_l4";
					reg = <0x4300 0x100>;
					status = "disabled";
				};

				regulator@4400 {
					compatible = "qcom,qpnp-regulator";
					regulator-name = "9635_l5";
					reg = <0x4400 0x100>;
					status = "disabled";
				};

				regulator@4500 {
					compatible = "qcom,qpnp-regulator";
					regulator-name = "9635_l6";
					reg = <0x4500 0x100>;
					status = "disabled";
				};

				regulator@4600 {
					compatible = "qcom,qpnp-regulator";
					regulator-name = "9635_l7";
					reg = <0x4600 0x100>;
					status = "disabled";
				};

				regulator@4700 {
					compatible = "qcom,qpnp-regulator";
					regulator-name = "9635_l8";
					reg = <0x4700 0x100>;
					status = "disabled";
				};

				regulator@4800 {
					compatible = "qcom,qpnp-regulator";
					regulator-name = "9635_l9";
					reg = <0x4800 0x100>;
					status = "disabled";
				};

				regulator@4900 {
					compatible = "qcom,qpnp-regulator";
					regulator-name = "9635_l10";
					reg = <0x4900 0x100>;
					status = "disabled";
				};

				regulator@4a00 {
					compatible = "qcom,qpnp-regulator";
					regulator-name = "9635_l11";
					reg = <0x4a00 0x100>;
					status = "disabled";
				};

				regulator@4b00 {
					compatible = "qcom,qpnp-regulator";
					regulator-name = "9635_l12";
					reg = <0x4b00 0x100>;
					status = "disabled";
				};

				regulator@4c00 {
					compatible = "qcom,qpnp-regulator";
					regulator-name = "9635_l13";
					reg = <0x4c00 0x100>;
					status = "disabled";
				};

				regulator@4d00 {
					compatible = "qcom,qpnp-regulator";
					regulator-name = "9635_l14";
					reg = <0x4d00 0x100>;
					status = "disabled";
				};

				regulator@4e00 {
					compatible = "qcom,qpnp-regulator";
					regulator-name = "9635_l15";
					reg = <0x4e00 0x100>;
					status = "disabled";
				};

				regulator@4f00 {
					compatible = "qcom,qpnp-regulator";
					regulator-name = "9635_l16";
					reg = <0x4f00 0x100>;
					status = "disabled";
				};
			};
		};

		qcom,sps@f9980000 {
			compatible = "qcom,msm_sps";
			reg = <0xf9984000 0x15000 0xf9999000 0xb000 0xfe803000 0xd000 0xfe805000 0x1000>;
			interrupts = <0x0 0x5e 0x0>;
		};

		qcom,pcie@fc520000 {
			compatible = "qcom,msm_pcie";
			cell-index = <0x0>;
			qcom,ctrl-amt = <0x1>;
			reg = <0xfc520000 0x2000 0xfc526000 0x1000 0x80000000 0x1000 0x80001000 0x1000 0x80100000 0x1000 0x80200000 0x100000 0x80300000 0xd00000>;
			reg-names = "parf", "phy", "dm_core", "elbi", "conf", "io", "bars";
			#address-cells = <0x0>;
			interrupt-parent = <0x15>;
			interrupts = <0x0 0x1 0x2 0x3 0x4 0x5 0x6 0x7 0x8 0x9 0xa 0xb 0xc>;
			#interrupt-cells = <0x1>;
			interrupt-map-mask = <0xffffffff>;
			interrupt-map = <0x0 0x1 0x0 0x29 0x0 0x1 0x1 0x0 0x2a 0x0 0x2 0x1 0x0 0x2b 0x0 0x3 0x1 0x0 0x2c 0x0 0x4 0x1 0x0 0x2d 0x0 0x5 0x1 0x0 0x2e 0x0 0x6 0x1 0x0 0x2f 0x0 0x7 0x1 0x0 0x30 0x0 0x8 0x1 0x0 0x31 0x0 0x9 0x1 0x0 0x32 0x0 0xa 0x1 0x0 0x33 0x0 0xb 0x1 0x0 0x34 0x0 0xc 0x11 0x41 0x2>;
			interrupt-names = "int_msi", "int_a", "int_b", "int_c", "int_d", "int_pls_pme", "int_pme_legacy", "int_pls_err", "int_aer_legacy", "int_pls_link_up", "int_pls_link_down", "int_bridge_flush_n", "int_wake";
			perst-gpio = <0x11 0x3d 0x0>;
			wake-gpio = <0x11 0x41 0x0>;
			clkreq-gpio = <0x11 0x40 0x0>;
			gdsc-vdd-supply = <0x16>;
			vreg-1.8-supply = <0x17>;
			vreg-0.9-supply = <0x18>;
			qcom,vreg-1.8-voltage-level = <0x1b7740 0x1b7740 0x3e8>;
			qcom,vreg-0.9-voltage-level = <0xe7ef0 0xe7ef0 0x5dc0>;
			qcom,l1ss-supported;
			qcom,n-fts = <0x50>;
			qcom,ep-latency = <0xa>;
			clock-names = "pcie_0_pipe_clk", "pcie_0_ref_clk_src", "pcie_0_aux_clk", "pcie_0_cfg_ahb_clk", "pcie_0_mstr_axi_clk", "pcie_0_slv_axi_clk", "pcie_0_ldo";
			max-clock-frequency-hz = <0x7735940 0x0 0xf4240 0x0 0x0 0x0 0x0>;
			qcom,msm-bus,name = "pcie0";
			qcom,msm-bus,num-cases = <0x2>;
			qcom,msm-bus,num-paths = <0x1>;
			qcom,msm-bus,vectors-KBps = <0x2d 0x200 0x0 0x0 0x2d 0x200 0x1f4 0x320>;
			linux,phandle = <0x15>;
			phandle = <0x15>;
		};

		spi@f9924000 {
			compatible = "qcom,spi-qup-v2";
			#address-cells = <0x1>;
			#size-cells = <0x0>;
			reg-names = "spi_physical", "spi_bam_physical";
			reg = <0xf9924000 0x1000 0xf9904000 0x19000>;
			interrupt-names = "spi_irq", "spi_bam_irq";
			interrupts = <0x0 0x60 0x0 0x0 0xee 0x0>;
			spi-max-frequency = <0x249f00>;
			qcom,gpio-mosi = <0x11 0x4 0x0>;
			qcom,gpio-miso = <0x11 0x5 0x0>;
			qcom,gpio-clk = <0x11 0x7 0x0>;
			qcom,gpio-cs0 = <0x11 0x6 0x0>;
			qcom,infinite-mode = <0x0>;
			qcom,use-bam;
			qcom,ver-reg-exists;
			qcom,bam-consumer-pipe-index = <0xe>;
			qcom,bam-producer-pipe-index = <0xf>;
			qcom,master-id = <0x56>;
			status = "disabled";
		};

		rng@f9bff000 {
			compatible = "qcom,msm-rng";
			reg = <0xf9bff000 0x200>;
			qcom,msm-rng-iface-clk;
			qcom,msm-bus,name = "msm-rng-noc";
			qcom,msm-bus,num-cases = <0x2>;
			qcom,msm-bus,num-paths = <0x1>;
			qcom,msm-bus,vectors-KBps = <0x1 0x26a 0x0 0x0 0x1 0x26a 0x0 0x320>;
			status = "disabled";
		};

		qcom,ipc-spinlock@fd484000 {
			compatible = "qcom,ipc-spinlock-sfpb";
			reg = <0xfd484000 0x400>;
			qcom,num-locks = <0x8>;
		};

		qcom,smem@1100000 {
			compatible = "qcom,smem";
			reg = <0x1100000 0x100000 0xf9011000 0x1000 0xfc428000 0x4000>;
			reg-names = "smem", "irq-reg-base", "aux-mem1";

			qcom,smd-modem {
				compatible = "qcom,smd";
				qcom,smd-edge = <0x0>;
				qcom,smd-irq-offset = <0x8>;
				qcom,smd-irq-bitmask = <0x1000>;
				qcom,pil-string = "modem";
				interrupts = <0x0 0x19 0x1>;
			};

			qcom,smsm-modem {
				compatible = "qcom,smsm";
				qcom,smsm-edge = <0x0>;
				qcom,smsm-irq-offset = <0x8>;
				qcom,smsm-irq-bitmask = <0x2000>;
				interrupts = <0x0 0x1a 0x1>;
			};

			qcom,smd-adsp {
				compatible = "qcom,smd";
				qcom,smd-edge = <0x1>;
				qcom,smd-irq-offset = <0x8>;
				qcom,smd-irq-bitmask = <0x100>;
				qcom,pil-string = "adsp";
				interrupts = <0x0 0x9c 0x1>;
			};

			qcom,smsm-adsp {
				compatible = "qcom,smsm";
				qcom,smsm-edge = <0x1>;
				qcom,smsm-irq-offset = <0x8>;
				qcom,smsm-irq-bitmask = <0x200>;
				interrupts = <0x0 0x9d 0x1>;
			};

			qcom,smd-rpm {
				compatible = "qcom,smd";
				qcom,smd-edge = <0xf>;
				qcom,smd-irq-offset = <0x8>;
				qcom,smd-irq-bitmask = <0x1>;
				interrupts = <0x0 0xa8 0x1>;
				qcom,irq-no-suspend;
			};
		};

		qcom,rpm-smd {
			compatible = "qcom,rpm-smd";
			rpm-channel-name = "rpm_requests";
			rpm-channel-type = <0xf>;

			rpm-regulator-smpa1 {
				compatible = "qcom,rpm-smd-regulator-resource";
				qcom,resource-name = "smpa";
				qcom,resource-id = <0x1>;
				qcom,regulator-type = <0x1>;
				qcom,hpm-min-load = <0x186a0>;
				status = "okay";

				regulator-s1 {
					compatible = "qcom,rpm-smd-regulator";
					regulator-name = "9635_s1";
					qcom,set = <0x3>;
					status = "okay";
					regulator-min-microvolt = <0xaae60>;
					regulator-max-microvolt = <0x10c8e0>;
					qcom,init-voltage = <0xdbba0>;
					linux,phandle = <0x19>;
					phandle = <0x19>;
				};
			};

			rpm-regulator-smpa2 {
				compatible = "qcom,rpm-smd-regulator-resource";
				qcom,resource-name = "smpa";
				qcom,resource-id = <0x2>;
				qcom,regulator-type = <0x1>;
				qcom,hpm-min-load = <0x186a0>;
				status = "okay";

				regulator-s2 {
					compatible = "qcom,rpm-smd-regulator";
					regulator-name = "9635_s2";
					qcom,set = <0x3>;
					status = "okay";
					regulator-min-microvolt = <0x1312d0>;
					regulator-max-microvolt = <0x1312d0>;
					qcom,init-voltage = <0x1312d0>;
				};
			};

			rpm-regulator-smpa3 {
				compatible = "qcom,rpm-smd-regulator-resource";
				qcom,resource-name = "smpa";
				qcom,resource-id = <0x3>;
				qcom,regulator-type = <0x1>;
				qcom,hpm-min-load = <0x186a0>;
				status = "okay";

				regulator-s3 {
					compatible = "qcom,rpm-smd-regulator";
					regulator-name = "9635_s3";
					qcom,set = <0x3>;
					status = "okay";
					regulator-min-microvolt = <0xa4cb8>;
					regulator-max-microvolt = <0x112a88>;
					qcom,init-voltage = <0xa4cb8>;
					linux,phandle = <0x1b>;
					phandle = <0x1b>;
				};
			};

			rpm-regulator-smpa4 {
				compatible = "qcom,rpm-smd-regulator-resource";
				qcom,resource-name = "smpa";
				qcom,resource-id = <0x4>;
				qcom,regulator-type = <0x1>;
				qcom,hpm-min-load = <0x186a0>;
				status = "okay";

				regulator-s4 {
					compatible = "qcom,rpm-smd-regulator";
					regulator-name = "9635_s4";
					qcom,set = <0x3>;
					status = "okay";
					regulator-min-microvolt = <0x1b7740>;
					regulator-max-microvolt = <0x1c3a90>;
					qcom,init-voltage = <0x1b7740>;
					linux,phandle = <0x37>;
					phandle = <0x37>;
				};
			};

			rpm-regulator-smpa5 {
				compatible = "qcom,rpm-smd-regulator-resource";
				qcom,resource-name = "smpa";
				qcom,resource-id = <0x5>;
				qcom,regulator-type = <0x1>;
				qcom,hpm-min-load = <0x186a0>;
				status = "okay";

				regulator-s5 {
					compatible = "qcom,rpm-smd-regulator";
					regulator-name = "9635_s5";
					qcom,set = <0x3>;
					status = "okay";
					regulator-min-microvolt = <0xf4240>;
					regulator-max-microvolt = <0xf4240>;
					qcom,init-voltage = <0xf4240>;
				};
			};

			rpm-regulator-ldoa1 {
				compatible = "qcom,rpm-smd-regulator-resource";
				qcom,resource-name = "ldoa";
				qcom,resource-id = <0x1>;
				qcom,regulator-type = <0x0>;
				qcom,hpm-min-load = <0x2710>;
				status = "okay";

				regulator-l1 {
					compatible = "qcom,rpm-smd-regulator";
					regulator-name = "9635_l1";
					qcom,set = <0x3>;
					status = "okay";
					regulator-min-microvolt = <0x12b128>;
					regulator-max-microvolt = <0x1312d0>;
					qcom,init-voltage = <0x12b128>;
					linux,phandle = <0x3a>;
					phandle = <0x3a>;
				};
			};

			rpm-regulator-ldoa2 {
				compatible = "qcom,rpm-smd-regulator-resource";
				qcom,resource-name = "ldoa";
				qcom,resource-id = <0x2>;
				qcom,regulator-type = <0x0>;
				qcom,hpm-min-load = <0x2710>;
				status = "okay";

				regulator-l2 {
					compatible = "qcom,rpm-smd-regulator";
					regulator-name = "9635_l2";
					qcom,set = <0x3>;
					status = "okay";
					regulator-min-microvolt = <0x124f80>;
					regulator-max-microvolt = <0x124f80>;
					qcom,init-voltage = <0x124f80>;
					linux,phandle = <0x27>;
					phandle = <0x27>;
				};
			};

			rpm-regulator-ldoa3 {
				compatible = "qcom,rpm-smd-regulator-resource";
				qcom,resource-name = "ldoa";
				qcom,resource-id = <0x3>;
				qcom,regulator-type = <0x0>;
				qcom,hpm-min-load = <0x2710>;
				status = "okay";

				regulator-l3 {
					compatible = "qcom,rpm-smd-regulator";
					regulator-name = "9635_l3";
					qcom,set = <0x3>;
					status = "disabled";
				};

				regulator-l3-corner {
					compatible = "qcom,rpm-smd-regulator";
					regulator-name = "9635_l3_corner";
					qcom,set = <0x3>;
					regulator-min-microvolt = <0x1>;
					regulator-max-microvolt = <0x7>;
					qcom,use-voltage-corner;
					qcom,consumer-supplies = "vdd_dig", "";
					linux,phandle = <0x1a>;
					phandle = <0x1a>;
				};

				regulator-l3-corner-ao {
					compatible = "qcom,rpm-smd-regulator";
					regulator-name = "9635_l3_corner_ao";
					qcom,set = <0x1>;
					regulator-min-microvolt = <0x1>;
					regulator-max-microvolt = <0x7>;
					qcom,use-voltage-corner;
					qcom,consumer-supplies = "vdd_dig_ao", "";
					linux,phandle = <0x29>;
					phandle = <0x29>;
				};

				regulator-l3-floor-corner {
					compatible = "qcom,rpm-smd-regulator";
					regulator-name = "9635_l3_floor_corner";
					qcom,set = <0x3>;
					regulator-min-microvolt = <0x1>;
					regulator-max-microvolt = <0x7>;
					qcom,use-voltage-floor-corner;
				};
			};

			rpm-regulator-ldoa4 {
				compatible = "qcom,rpm-smd-regulator-resource";
				qcom,resource-name = "ldoa";
				qcom,resource-id = <0x4>;
				qcom,regulator-type = <0x0>;
				qcom,hpm-min-load = <0x2710>;
				status = "okay";

				regulator-l4 {
					compatible = "qcom,rpm-smd-regulator";
					regulator-name = "9635_l4";
					qcom,set = <0x3>;
					status = "okay";
					regulator-min-microvolt = <0xe7ef0>;
					regulator-max-microvolt = <0xe7ef0>;
					qcom,init-voltage = <0xe7ef0>;
					linux,phandle = <0x18>;
					phandle = <0x18>;
				};
			};

			rpm-regulator-ldoa5 {
				compatible = "qcom,rpm-smd-regulator-resource";
				qcom,resource-name = "ldoa";
				qcom,resource-id = <0x5>;
				qcom,regulator-type = <0x0>;
				qcom,hpm-min-load = <0x2710>;
				status = "okay";

				regulator-l5 {
					compatible = "qcom,rpm-smd-regulator";
					regulator-name = "9635_l5";
					qcom,set = <0x3>;
					status = "okay";
					regulator-min-microvolt = <0x19f0a0>;
					regulator-max-microvolt = <0x1b7740>;
					qcom,init-voltage = <0x1b7740>;
				};
			};

			rpm-regulator-ldoa6 {
				compatible = "qcom,rpm-smd-regulator-resource";
				qcom,resource-name = "ldoa";
				qcom,resource-id = <0x6>;
				qcom,regulator-type = <0x0>;
				qcom,hpm-min-load = <0x2710>;
				status = "okay";

				regulator-l6 {
					compatible = "qcom,rpm-smd-regulator";
					regulator-name = "9635_l6";
					qcom,set = <0x3>;
					status = "okay";
					regulator-min-microvolt = <0x1b7740>;
					regulator-max-microvolt = <0x1b7740>;
					qcom,init-voltage = <0x1b7740>;
					linux,phandle = <0x39>;
					phandle = <0x39>;
				};
			};

			rpm-regulator-ldoa7 {
				compatible = "qcom,rpm-smd-regulator-resource";
				qcom,resource-name = "ldoa";
				qcom,resource-id = <0x7>;
				qcom,regulator-type = <0x0>;
				qcom,hpm-min-load = <0x2710>;
				status = "okay";

				regulator-l7 {
					compatible = "qcom,rpm-smd-regulator";
					regulator-name = "9635_l7";
					qcom,set = <0x3>;
					status = "okay";
					regulator-min-microvolt = <0x1b7740>;
					regulator-max-microvolt = <0x1b7740>;
					qcom,init-voltage = <0x1b7740>;
					linux,phandle = <0x1c>;
					phandle = <0x1c>;
				};
			};

			rpm-regulator-ldoa8 {
				compatible = "qcom,rpm-smd-regulator-resource";
				qcom,resource-name = "ldoa";
				qcom,resource-id = <0x8>;
				qcom,regulator-type = <0x0>;
				qcom,hpm-min-load = <0x2710>;
				status = "okay";

				regulator-l8 {
					compatible = "qcom,rpm-smd-regulator";
					regulator-name = "9635_l8";
					qcom,set = <0x3>;
					status = "okay";
					regulator-min-microvolt = <0x1b7740>;
					regulator-max-microvolt = <0x1b7740>;
					qcom,init-voltage = <0x1b7740>;
					linux,phandle = <0x17>;
					phandle = <0x17>;
				};
			};

			rpm-regulator-ldoa9 {
				compatible = "qcom,rpm-smd-regulator-resource";
				qcom,resource-name = "ldoa";
				qcom,resource-id = <0x9>;
				qcom,regulator-type = <0x0>;
				qcom,hpm-min-load = <0x2710>;
				status = "okay";

				regulator-l9 {
					compatible = "qcom,rpm-smd-regulator";
					regulator-name = "9635_l9";
					qcom,set = <0x3>;
					status = "okay";
					regulator-min-microvolt = <0xf4240>;
					regulator-max-microvolt = <0xf4240>;
					qcom,init-voltage = <0xf4240>;
				};
			};

			rpm-regulator-ldoa10 {
				compatible = "qcom,rpm-smd-regulator-resource";
				qcom,resource-name = "ldoa";
				qcom,resource-id = <0xa>;
				qcom,regulator-type = <0x0>;
				qcom,hpm-min-load = <0x2710>;
				status = "okay";

				regulator-l10 {
					compatible = "qcom,rpm-smd-regulator";
					regulator-name = "9635_l10";
					qcom,set = <0x3>;
					status = "okay";
					regulator-min-microvolt = <0x2eebb8>;
					regulator-max-microvolt = <0x2eebb8>;
					qcom,init-voltage = <0x2eebb8>;
					linux,phandle = <0x22>;
					phandle = <0x22>;
				};
			};

			rpm-regulator-ldoa11 {
				compatible = "qcom,rpm-smd-regulator-resource";
				qcom,resource-name = "ldoa";
				qcom,resource-id = <0xb>;
				qcom,regulator-type = <0x0>;
				qcom,hpm-min-load = <0x2710>;
				status = "okay";

				regulator-l11 {
					compatible = "qcom,rpm-smd-regulator";
					regulator-name = "9635_l11";
					qcom,set = <0x3>;
					status = "okay";
					regulator-min-microvolt = <0x1b7740>;
					regulator-max-microvolt = <0x2b7cd0>;
					qcom,init-voltage = <0x1b7740>;
				};
			};

			rpm-regulator-ldoa12 {
				compatible = "qcom,rpm-smd-regulator-resource";
				qcom,resource-name = "ldoa";
				qcom,resource-id = <0xc>;
				qcom,regulator-type = <0x0>;
				qcom,hpm-min-load = <0x2710>;
				status = "okay";

				regulator-l12 {
					compatible = "qcom,rpm-smd-regulator";
					regulator-name = "9635_l12";
					qcom,set = <0x3>;
					status = "okay";
					regulator-min-microvolt = <0x2932e0>;
					regulator-max-microvolt = <0x2932e0>;
					qcom,init-voltage = <0x2932e0>;
				};
			};

			rpm-regulator-ldoa13 {
				compatible = "qcom,rpm-smd-regulator-resource";
				qcom,resource-name = "ldoa";
				qcom,resource-id = <0xd>;
				qcom,regulator-type = <0x0>;
				qcom,hpm-min-load = <0x2710>;
				status = "okay";

				regulator-l13 {
					compatible = "qcom,rpm-smd-regulator";
					regulator-name = "9635_l13";
					qcom,set = <0x3>;
					status = "okay";
					regulator-min-microvolt = <0x1b7740>;
					regulator-max-microvolt = <0x2b7cd0>;
					qcom,init-voltage = <0x1b7740>;
				};
			};

			rpm-regulator-ldoa14 {
				compatible = "qcom,rpm-smd-regulator-resource";
				qcom,resource-name = "ldoa";
				qcom,resource-id = <0xe>;
				qcom,regulator-type = <0x0>;
				qcom,hpm-min-load = <0x2710>;
				status = "okay";

				regulator-l14 {
					compatible = "qcom,rpm-smd-regulator";
					regulator-name = "9635_l14";
					qcom,set = <0x3>;
					status = "okay";
					regulator-min-microvolt = <0x1b7740>;
					regulator-max-microvolt = <0x2b7cd0>;
					qcom,init-voltage = <0x1b7740>;
					linux,phandle = <0x2d>;
					phandle = <0x2d>;
				};
			};

			rpm-regulator-ldoa15 {
				compatible = "qcom,rpm-smd-regulator-resource";
				qcom,resource-name = "ldoa";
				qcom,resource-id = <0xf>;
				qcom,regulator-type = <0x0>;
				qcom,hpm-min-load = <0x2710>;
				status = "okay";

				regulator-l15 {
					compatible = "qcom,rpm-smd-regulator";
					regulator-name = "9635_l15";
					qcom,set = <0x3>;
					status = "okay";
					regulator-min-microvolt = <0x1b7740>;
					regulator-max-microvolt = <0x1b7740>;
					qcom,init-voltage = <0x1b7740>;
					linux,phandle = <0x38>;
					phandle = <0x38>;
				};
			};

			rpm-regulator-ldoa16 {
				compatible = "qcom,rpm-smd-regulator-resource";
				qcom,resource-name = "ldoa";
				qcom,resource-id = <0x10>;
				qcom,regulator-type = <0x0>;
				qcom,hpm-min-load = <0x2710>;
				status = "okay";

				regulator-l16 {
					compatible = "qcom,rpm-smd-regulator";
					regulator-name = "9635_l16";
					qcom,set = <0x3>;
					status = "okay";
					regulator-min-microvolt = <0xe7ef0>;
					regulator-max-microvolt = <0xe7ef0>;
					qcom,init-voltage = <0xe7ef0>;
				};
			};
		};

		qcom,wdt@f9017000 {
			compatible = "qcom,msm-watchdog";
			reg = <0xf9017000 0x1000>;
			interrupts = <0x1 0x2 0x0 0x1 0x1 0x0>;
			qcom,bark-time = <0x2af8>;
			qcom,pet-time = <0x2710>;
		};

		jtagfuse@fc4be024 {
			compatible = "qcom,jtag-fuse";
			reg = <0xfc4be024 0x8>;
			reg-names = "fuse-base";
		};

		jtagmm@fc342000 {
			compatible = "qcom,jtag-mm";
			reg = <0xfc342000 0x1000 0xfc340000 0x1000>;
			reg-names = "etm-base", "debug-base";
		};

		qcom,msm-rtb {
			compatible = "qcom,msm-rtb";
			qcom,rtb-size = <0x1000>;
		};

		qcom,mss@fc880000 {
			compatible = "qcom,pil-q6v55-mss";
			reg = <0xfc880000 0x100 0xfd485000 0x400 0xfc820000 0x20 0xfc401680 0x4>;
			reg-names = "qdsp6_base", "halt_base", "rmb_base", "restart_reg";
			interrupts = <0x0 0x18 0x1>;
			vdd_mss-supply = <0x19>;
			vdd_cx-supply = <0x1a>;
			vdd_mx-supply = <0x1b>;
			vdd_mx-uV = <0x7>;
			vdd_pll-supply = <0x1c>;
			qcom,vdd_pll = <0x1b7740>;
			qcom,override-acc;
			qcom,firmware-name = "modem";
			qcom,pil-self-auth;
			qcom,mba-image-is-not-elf;
			qcom,gpio-err-fatal = <0x1d 0x0 0x0>;
			qcom,gpio-err-ready = <0x1d 0x1 0x0>;
			qcom,gpio-proxy-unvote = <0x1d 0x2 0x0>;
			qcom,gpio-stop-ack = <0x1d 0x3 0x0>;
			qcom,gpio-force-stop = <0x1e 0x0 0x0>;
		};

		qcom,ipa@fd4c0000 {
			compatible = "qcom,ipa";
			reg = <0xfd4c0000 0x29000 0xfd4c4000 0x15820>;
			reg-names = "ipa-base", "bam-base";
			interrupts = <0x0 0xfc 0x0 0x0 0xfe 0x0>;
			interrupt-names = "ipa-irq", "bam-irq";
			qcom,ipa-hw-ver = <0x3>;
			qcom,ipa-hw-mode = <0x0>;
			qcom,ee = <0x2>;
			qcom,use-ipa-tethering-bridge;
		};

		qcom,rmnet-ipa {
			compatible = "qcom,rmnet-ipa";
		};

		ssusb@f9200000 {
			compatible = "qcom,dwc-usb3-msm";
			reg = <0xf9200000 0xfc000 0xfd4ab000 0x4>;
			#address-cells = <0x1>;
			#size-cells = <0x1>;
			ranges;
			interrupt-parent = <0x1f>;
			interrupts = <0x0 0x1 0x2>;
			#interrupt-cells = <0x1>;
			interrupt-map-mask = <0x0 0xffffffff>;
			interrupt-map = <0x0 0x0 0x1 0x0 0x85 0x0 0x0 0x1 0x1 0x0 0xb4 0x0 0x0 0x2 0x20 0x0 0x0 0x9 0x0>;
			interrupt-names = "hs_phy_irq", "pwr_event_irq", "pmic_id_irq";
			USB3_GDSC-supply = <0x21>;
			vdda33-supply = <0x22>;
			qcom,otg-capability;
			qcom,usb-dbm = <0x23>;
			qcom,msm-bus,name = "usb3";
			qcom,msm-bus,num-cases = <0x2>;
			qcom,msm-bus,num-paths = <0x1>;
			qcom,msm-bus,vectors-KBps = <0x3d 0x200 0x0 0x0 0x3d 0x200 0x3a980 0xea600>;
			qcom,reset_hsphy_sleep_clk_on_init;
			qcom,power-collapse-on-cable-disconnect;
			qcom,por-after-power-collapse;
			qcom,lpm-to-suspend-delay-ms = <0x7d0>;
			qcom,dwc-usb3-msm-tx-fifo-size = <0x7400>;
			vbus_dwc3-supply = <0x24>;
			linux,phandle = <0x1f>;
			phandle = <0x1f>;

			dwc3@f9200000 {
				compatible = "synopsys,dwc3";
				reg = <0xf9200000 0xfc000>;
				interrupt-parent = <0x1>;
				interrupts = <0x0 0x83 0x0 0x0 0xb3 0x0>;
				interrupt-names = "irq", "otg_irq";
				usb-phy = <0x25 0x26>;
				snps,nominal-elastic-buffer;
				snps,core-reset-after-phy-init;
				snps,hsphy-auto-suspend-disable;
				snps,hird_thresh = <0x10>;
				snps,bus-suspend-enable;
				tx-fifo-resize;
			};
		};

		android_usb@fe8050c8 {
			reg = <0xfe8050c8 0xc8>;
			compatible = "qcom,android-usb";
			qcom,android-usb-swfi-latency = <0x64>;
		};

		hsphy@f92f8800 {
			compatible = "qcom,usb-hsphy";
			reg = <0xf92f8800 0x3ff>;
			qcom,hsphy-init = <0xd191a4>;
			vdd-supply = <0x1a>;
			vdda18-supply = <0x17>;
			vdda33-supply = <0x22>;
			qcom,vdd-voltage-level = <0x1 0x5 0x7>;
			qcom,ext-vbus-id;
			qcom,vbus-valid-override;
			qcom,set-pllbtune;
			linux,phandle = <0x25>;
			phandle = <0x25>;
		};

		ssphy@f9b38000 {
			compatible = "qcom,usb-ssphy-qmp";
			reg = <0xf9b38000 0x16c 0xf9b3e000 0x3ff>;
			reg-names = "qmp_phy_base", "qmp_ahb2phy_base";
			vdd-supply = <0x18>;
			vdda18-supply = <0x17>;
			qcom,vdd-voltage-level = <0x0 0xdbba0 0x100590>;
			qcom,vbus-valid-override;
			qcom,qmp-misc-config;
			linux,phandle = <0x26>;
			phandle = <0x26>;
		};

		dbm@f92f8000 {
			compatible = "qcom,usb-dbm-1p5";
			reg = <0xf92f8000 0x1000>;
			qcom,reset-ep-after-lpm-resume;
			linux,phandle = <0x23>;
			phandle = <0x23>;
		};

		qcom,usbbam@f9304000 {
			compatible = "qcom,usb-bam-msm";
			reg = <0xf9304000 0x8814>;
			reg-names = "ssusb";
			interrupts = <0x0 0x84 0x0>;
			interrupt-names = "ssusb";
			qcom,usb-bam-fifo-baseaddr = <0xfe803000>;
			qcom,usb-bam-num-pipes = <0x10>;
			qcom,ignore-core-reset-ack;
			qcom,disable-clk-gating;
			qcom,usb-bam-override-threshold = <0x4001>;
			qcom,usb-bam-max-mbps-highspeed = <0x190>;
			qcom,usb-bam-max-mbps-superspeed = <0xe10>;

			qcom,pipe0 {
				label = "ssusb-ipa-out-0";
				qcom,usb-bam-mem-type = <0x2>;
				qcom,bam-type = <0x0>;
				qcom,dir = <0x0>;
				qcom,pipe-num = <0x0>;
				qcom,peer-bam = <0x2>;
				qcom,src-bam-physical-address = <0xf9304000>;
				qcom,src-bam-pipe-index = <0x1>;
				qcom,data-fifo-size = <0x8000>;
				qcom,descriptor-fifo-size = <0x2000>;
				qcom,reset-bam-on-connect;
				qcom,pipe-connection-type = <0x1>;
			};

			qcom,pipe1 {
				label = "ssusb-ipa-in-0";
				qcom,usb-bam-mem-type = <0x2>;
				qcom,bam-type = <0x0>;
				qcom,dir = <0x1>;
				qcom,pipe-num = <0x0>;
				qcom,peer-bam = <0x2>;
				qcom,dst-bam-physical-address = <0xf9304000>;
				qcom,dst-bam-pipe-index = <0x0>;
				qcom,data-fifo-size = <0x8000>;
				qcom,descriptor-fifo-size = <0x2000>;
				qcom,reset-bam-on-connect;
			};

			qcom,pipe2 {
				label = "ssusb-qdss-in-0";
				qcom,usb-bam-mem-type = <0x3>;
				qcom,bam-type = <0x0>;
				qcom,dir = <0x1>;
				qcom,pipe-num = <0x0>;
				qcom,peer-bam = <0x1>;
				qcom,src-bam-physical-address = <0xfc37c000>;
				qcom,src-bam-pipe-index = <0x0>;
				qcom,dst-bam-physical-address = <0xf9304000>;
				qcom,dst-bam-pipe-index = <0x2>;
				qcom,data-fifo-offset = <0x0>;
				qcom,data-fifo-size = <0xc00>;
				qcom,descriptor-fifo-offset = <0xc00>;
				qcom,descriptor-fifo-size = <0x400>;
				qcom,reset-bam-on-connect;
			};

			qcom,pipe3 {
				label = "ssusb-ipa-out-1";
				qcom,usb-bam-mem-type = <0x2>;
				qcom,bam-type = <0x0>;
				qcom,dir = <0x0>;
				qcom,pipe-num = <0x1>;
				qcom,peer-bam = <0x2>;
				qcom,src-bam-physical-address = <0xf9304000>;
				qcom,src-bam-pipe-index = <0x3>;
				qcom,data-fifo-size = <0x8000>;
				qcom,descriptor-fifo-size = <0x2000>;
				qcom,reset-bam-on-connect;
				qcom,pipe-connection-type = <0x1>;
			};

			qcom,pipe4 {
				label = "ssusb-ipa-in-1";
				qcom,usb-bam-mem-type = <0x2>;
				qcom,bam-type = <0x0>;
				qcom,dir = <0x1>;
				qcom,pipe-num = <0x1>;
				qcom,peer-bam = <0x2>;
				qcom,dst-bam-physical-address = <0xf9304000>;
				qcom,dst-bam-pipe-index = <0x2>;
				qcom,data-fifo-size = <0x8000>;
				qcom,descriptor-fifo-size = <0x2000>;
				qcom,reset-bam-on-connect;
			};

			qcom,pipe5 {
				label = "ssusb-ipa-out-2";
				qcom,usb-bam-mem-type = <0x2>;
				qcom,bam-type = <0x0>;
				qcom,dir = <0x0>;
				qcom,pipe-num = <0x2>;
				qcom,peer-bam = <0x2>;
				qcom,src-bam-physical-address = <0xf9304000>;
				qcom,src-bam-pipe-index = <0x5>;
				qcom,data-fifo-size = <0x8000>;
				qcom,descriptor-fifo-size = <0x2000>;
				qcom,reset-bam-on-connect;
				qcom,pipe-connection-type = <0x1>;
			};

			qcom,pipe6 {
				label = "ssusb-ipa-in-2";
				qcom,usb-bam-mem-type = <0x2>;
				qcom,bam-type = <0x0>;
				qcom,dir = <0x1>;
				qcom,pipe-num = <0x2>;
				qcom,peer-bam = <0x2>;
				qcom,dst-bam-physical-address = <0xf9304000>;
				qcom,dst-bam-pipe-index = <0x4>;
				qcom,data-fifo-size = <0x8000>;
				qcom,descriptor-fifo-size = <0x2000>;
				qcom,reset-bam-on-connect;
			};

			qcom,pipe7 {
				label = "ssusb-ipa-out-3";
				qcom,usb-bam-mem-type = <0x2>;
				qcom,bam-type = <0x0>;
				qcom,dir = <0x0>;
				qcom,pipe-num = <0x3>;
				qcom,peer-bam = <0x2>;
				qcom,src-bam-physical-address = <0xf9304000>;
				qcom,src-bam-pipe-index = <0x6>;
				qcom,data-fifo-size = <0x8000>;
				qcom,descriptor-fifo-size = <0x2000>;
				qcom,reset-bam-on-connect;
				qcom,pipe-connection-type = <0x1>;
			};

			qcom,pipe8 {
				label = "ssusb-ipa-in-3";
				qcom,usb-bam-mem-type = <0x2>;
				qcom,bam-type = <0x0>;
				qcom,dir = <0x1>;
				qcom,pipe-num = <0x3>;
				qcom,peer-bam = <0x2>;
				qcom,dst-bam-physical-address = <0xf9304000>;
				qcom,dst-bam-pipe-index = <0x7>;
				qcom,data-fifo-size = <0x8000>;
				qcom,descriptor-fifo-size = <0x2000>;
				qcom,reset-bam-on-connect;
			};
		};

		hsic_host@f9a15000 {
			compatible = "qcom,hsic-host";
			reg = <0xf9a15000 0x400>;
			interrupts = <0x0 0x88 0x0 0x0 0x94 0x0>;
			interrupt-names = "core_irq", "async_irq";
			HSIC_VDDCX-supply = <0x27>;
			HSIC_GDSC-supply = <0x28>;
			qcom,msm-bus,name = "hsic";
			qcom,msm-bus,num-cases = <0x2>;
			qcom,msm-bus,num-paths = <0x1>;
			qcom,msm-bus,vectors-KBps = <0x55 0x200 0x0 0x0 0x55 0x200 0x9c40 0x9c400>;
			qcom,pool-64-bit-align;
			qcom,ahb-async-bridge-bypass;
			hsic,disable-cerr;
			qcom,disable-internal-clk-gating;
		};

		qcom,nand@f9ac0000 {
			compatible = "qcom,msm-nand";
			reg = <0xf9ac0000 0x1000 0xf9ac4000 0x8000>;
			reg-names = "nand_phys", "bam_phys";
			interrupts = <0x0 0xf7 0x0>;
			interrupt-names = "bam_irq";
			qcom,msm-bus,name = "qpic_nand";
			qcom,msm-bus,num-cases = <0x2>;
			qcom,msm-bus,num-paths = <0x1>;
			qcom,msm-bus,vectors-KBps = <0x5b 0x200 0x0 0x0 0x5b 0x200 0x61a80 0xc3500>;
		};

		qcom,mpm2-sleep-counter@fc4a3000 {
			compatible = "qcom,mpm2-sleep-counter";
			reg = <0xfc4a3000 0x1000>;
			clock-frequency = <0x8000>;
		};

		tsens@fc4a8000 {
			compatible = "qcom,mdm9630-tsens";
			reg = <0xfc4a8000 0x2000 0xfc4bc000 0x1000>;
			reg-names = "tsens_physical", "tsens_eeprom_physical";
			interrupts = <0x0 0xb8 0x0>;
			qcom,sensors = <0x5>;
			qcom,slope = <0xb55 0xb1e 0xc80 0xc80 0xc80>;
		};

		qcom,clock-a7@f9010008 {
			compatible = "qcom,clock-a7-9630";
			reg = <0xf9010008 0x8>;
			reg-names = "rcg-base";
			clock-names = "clk-1", "clk-5";
			qcom,speed0-bin-v0 = <0x0 0x0 0x11e1a300 0x4 0x2eebb800 0x5 0x44aa2000 0x7>;
			cpu-vdd-supply = <0x29>;
		};

		qcom,cpubw {
			compatible = "qcom,cpubw";
			qcom,cpu-mem-ports = <0x1 0x200>;
			qcom,bw-tbl = <0x4f2 0x9ec 0xbeb>;
		};

		qcom,msm-cpufreq@0 {
			reg = <0x0 0x4>;
			compatible = "qcom,msm-cpufreq";
			qcom,cpufreq-table = <0x493e0 0x4f2 0x927c0 0x4f2 0xc0300 0x9ec 0xf3c00 0xbeb 0x119400 0xbeb>;
		};

		qcom,msm-thermal {
			compatible = "qcom,msm-thermal";
			qcom,sensor-id = <0x0>;
			qcom,poll-ms = <0xfa>;
			qcom,limit-temp = <0x3c>;
			qcom,temp-hysteresis = <0xa>;
			qcom,freq-step = <0x2>;
			qcom,freq-control-mask = <0x0>;
			qcom,mx-restriction-temp = <0x5>;
			qcom,mx-restriction-temp-hysteresis = <0x5>;
			qcom,mx-retention-min = <0xad570>;
			vdd-mx-supply = <0x1b>;
			qcom,vdd-restriction-temp = <0x5>;
			qcom,vdd-restriction-temp-hysteresis = <0xa>;
			vdd-dig-supply = <0x1a>;

			qcom,vdd-dig-rstr {
				qcom,vdd-rstr-reg = "vdd-dig";
				qcom,levels = <0x5 0x7 0x7>;
				qcom,min-level = <0x1>;
			};
		};

		qcom,lpass@fe200000 {
			compatible = "qcom,pil-tz-generic";
			reg = <0xfe200000 0x100>;
			interrupts = <0x0 0xa2 0x1>;
			vdd_cx-supply = <0x1a>;
			proxy-reg-names = "vdd_cx";
			vdd_cx-uV-uA = <0x7 0x186a0>;
			clock-names = "bus_clk", "xo";
			active-clock-names = "bus_clk";
			proxy-clock-names = "xo";
			qcom,pas-id = <0x1>;
			qcom,proxy-timeout-ms = <0x2710>;
			qcom,smem-id = <0x1a7>;
			qcom,firmware-name = "adsp";
			qcom,gpio-err-fatal = <0x2a 0x0 0x0>;
			qcom,gpio-proxy-unvote = <0x2a 0x2 0x0>;
			qcom,gpio-err-ready = <0x2a 0x1 0x0>;
			qcom,gpio-stop-ack = <0x2a 0x3 0x0>;
			qcom,gpio-force-stop = <0x2b 0x0 0x0>;
		};

		sdhci@f98a4900 {
			compatible = "qcom,sdhci-msm";
			reg = <0xf98a4900 0x11c 0xf98a4000 0x800>;
			reg-names = "hc_mem", "core_mem";
			interrupts = <0x0 0x7d 0x0 0x0 0xdd 0x0>;
			interrupt-names = "hc_irq", "pwr_irq";
			qcom,clk-rates = <0x61a80 0x1312d00 0x17d7840 0x2faf080 0x5f5e100 0xbebc200>;
			qcom,bus-width = <0x4>;
			qcom,cpu-dma-latency-us = <0xc8>;
			status = "ok";
			vdd-supply = <0x2c>;
			qcom,vdd-voltage-level = <0x2d0370 0x2d0370>;
			qcom,vdd-current-level = <0x2328 0xc3500>;
			vdd-io-supply = <0x2d>;
			qcom,vdd-io-voltage-level = <0x1b7740 0x2b7cd0>;
			qcom,vdd-io-current-level = <0x6 0x55f0>;
			pinctrl-names = "active", "sleep";
			pinctrl-0 = <0x2e 0x2f 0x30 0x31>;
			pinctrl-1 = <0x32 0x33 0x34 0x35>;
			qcom,nonremovable;
		};

		wcd9xxx-irq {
			compatible = "qcom,wcd9xxx-irq";
			interrupt-controller;
			#interrupt-cells = <0x1>;
			interrupt-parent = <0x11>;
			interrupts = <0x2b 0x0>;
			interrupt-names = "cdc-int";
			linux,phandle = <0x36>;
			phandle = <0x36>;
		};

		i2c@f9925000 {
			cell-index = <0x1>;
			compatible = "qcom,i2c-qup";
			#address-cells = <0x1>;
			#size-cells = <0x0>;
			reg-names = "qup_phys_addr";
			reg = <0xf9925000 0x1000>;
			interrupt-names = "qup_err_intr";
			interrupts = <0x0 0x61 0x0>;
			qcom,i2c-bus-freq = <0x61a80>;
			qcom,i2c-src-freq = <0x124f800>;
			qcom,sda-gpio = <0x11 0xa 0x0>;
			qcom,scl-gpio = <0x11 0xb 0x0>;
			qcom,master-id = <0x56>;

			wcd9xxx_codec@d {
				compatible = "qcom,wcd9xxx-i2c";
				reg = <0xd>;
				qcom,cdc-reset-gpio = <0x11 0x43 0x0>;
				interrupt-parent = <0x36>;
				interrupts = <0x0 0x1 0x2 0x3 0x4 0x5 0x6 0x7 0x8 0x9 0xa 0xb 0xc 0xd 0xe 0xf 0x10 0x11 0x12 0x13 0x14 0x15 0x16 0x17 0x18 0x19 0x1a 0x1b 0x1c>;
				cdc-vdd-buck-supply = <0x37>;
				qcom,cdc-vdd-buck-voltage = <0x1b7740 0x1b7740>;
				qcom,cdc-vdd-buck-current = <0x61a8>;
				cdc-vdd-tx-h-supply = <0x38>;
				qcom,cdc-vdd-tx-h-voltage = <0x1b7740 0x1b7740>;
				qcom,cdc-vdd-tx-h-current = <0x61a8>;
				cdc-vdd-rx-h-supply = <0x38>;
				qcom,cdc-vdd-rx-h-voltage = <0x1b7740 0x1b7740>;
				qcom,cdc-vdd-rx-h-current = <0x61a8>;
				cdc-vddpx-1-supply = <0x39>;
				qcom,cdc-vddpx-1-voltage = <0x1b7740 0x1b7740>;
				qcom,cdc-vddpx-1-current = <0x2710>;
				cdc-vdd-a-1p2v-supply = <0x3a>;
				qcom,cdc-vdd-a-1p2v-voltage = <0x12b128 0x12b128>;
				qcom,cdc-vdd-a-1p2v-current = <0x2710>;
				cdc-vddcx-1-supply = <0x27>;
				qcom,cdc-vddcx-1-voltage = <0x124f80 0x124f80>;
				qcom,cdc-vddcx-1-current = <0x2710>;
				cdc-vddcx-2-supply = <0x27>;
				qcom,cdc-vddcx-2-voltage = <0x124f80 0x124f80>;
				qcom,cdc-vddcx-2-current = <0x2710>;
				qcom,cdc-static-supplies = "cdc-vdd-buck", "cdc-vdd-tx-h", "cdc-vdd-rx-h", "cdc-vddpx-1", "cdc-vdd-a-1p2v", "cdc-vddcx-1", "cdc-vddcx-2";
				qcom,cdc-micbias-ldoh-v = <0x3>;
				qcom,cdc-micbias-cfilt1-mv = <0x708>;
				qcom,cdc-micbias-cfilt2-mv = <0xa8c>;
				qcom,cdc-micbias-cfilt3-mv = <0x708>;
				qcom,cdc-micbias1-cfilt-sel = <0x0>;
				qcom,cdc-micbias2-cfilt-sel = <0x1>;
				qcom,cdc-micbias3-cfilt-sel = <0x2>;
				qcom,cdc-micbias4-cfilt-sel = <0x2>;
				qcom,cdc-mclk-clk-rate = <0xbb8000>;
				qcom,cdc-micbias1-ext-cap;
				qcom,cdc-micbias2-ext-cap;
				qcom,cdc-micbias3-ext-cap;
			};

			wcd9xxx_codec@77 {
				compatible = "qcom,wcd9xxx-i2c";
				reg = <0x77>;
			};

			wcd9xxx_codec@66 {
				compatible = "qcom,wcd9xxx-i2c";
				reg = <0x66>;
			};

			wcd9xxx_codec@55 {
				compatible = "qcom,wcd9xxx-i2c";
				reg = <0x55>;
			};

			smb1357-charger@1c {
				compatible = "qcom,smb1357-charger";
				reg = <0x1c>;
				interrupt-parent = <0x11>;
				interrupts = <0x18 0x3>;
				qcom,float-voltage-mv = <0x10fe>;
				qcom,charging-timeout = <0x600>;
				qcom,recharge-thresh-mv = <0x64>;
				qcom,iterm-ma = <0x32>;
				qcom,temp-monitor-disabled;
				regulator-name = "smb1357_otg_supply";
				linux,phandle = <0x24>;
				phandle = <0x24>;
				qcom,bms-psy-name = "bms";
			};
		};

		i2c@f9927000 {
			cell-index = <0x3>;
			compatible = "qcom,i2c-qup";
			reg = <0xf9927000 0x1000>;
			#address-cells = <0x1>;
			#size-cells = <0x0>;
			reg-names = "qup_phys_addr";
			interrupts = <0x0 0x63 0x0>;
			interrupt-names = "qup_err_intr";
			qcom,i2c-bus-freq = <0x61a80>;
			qcom,i2c-src-freq = <0x124f800>;
			qcom,scl-gpio = <0x11 0x3c 0x0>;
			qcom,sda-gpio = <0x11 0x3b 0x0>;
			qcom,master-id = <0x58>;

			nxp,PCA9555AHF-leds@20 {
				compatible = "nxp,pca9555";
				reg = <0x20>;
				led_en_gpio = <0x11 0x38 0x0>;
			};
		};

		sound {
			compatible = "qcom,mdm9630-audio-taiko";
			qcom,model = "mdm9630-taiko-i2s-snd-card";
			qcom,audio-routing = "RX_BIAS", "MCLK", "LDO_H", "MCLK", "Ext Spk Bottom Pos", "LINEOUT1", "Ext Spk Bottom Neg", "LINEOUT3", "Ext Spk Top Pos", "LINEOUT2", "Ext Spk Top Neg", "LINEOUT4", "AMIC1", "MIC BIAS1 External", "MIC BIAS1 External", "Handset Mic", "AMIC2", "MIC BIAS2 External", "MIC BIAS2 External", "Headset Mic", "AMIC3", "MIC BIAS3 Internal1", "MIC BIAS3 Internal1", "ANCRight Headset Mic", "AMIC4", "MIC BIAS1 Internal2", "MIC BIAS1 Internal2", "ANCLeft Headset Mic", "DMIC1", "MIC BIAS1 External", "MIC BIAS1 External", "Digital Mic1", "DMIC2", "MIC BIAS1 External", "MIC BIAS1 External", "Digital Mic2", "DMIC3", "MIC BIAS3 External", "MIC BIAS3 External", "Digital Mic3", "DMIC4", "MIC BIAS3 External", "MIC BIAS3 External", "Digital Mic4", "DMIC5", "MIC BIAS4 External", "MIC BIAS4 External", "Digital Mic5", "DMIC6", "MIC BIAS4 External", "MIC BIAS4 External", "Digital Mic6";
			qcom,taiko-mclk-clk-freq = <0xbb8000>;
			qcom,prim-i2s-gpio-ws = <0x11 0xc 0x0>;
			qcom,prim-i2s-gpio-din = <0x11 0xd 0x0>;
			qcom,prim-i2s-gpio-dout = <0x11 0xe 0x0>;
			qcom,prim-i2s-gpio-sclk = <0x11 0xf 0x0>;
			qcom,prim-i2s-gpio-mclk = <0x11 0x47 0x0>;
			qcom,cdc-micbias2-headset-only;
		};

		qcom,msm-adsp-loader {
			compatible = "qcom,adsp-loader";
			qcom,adsp-state = <0x0>;
		};

		qcom,msm-pcm {
			compatible = "qcom,msm-pcm-dsp";
			qcom,msm-pcm-dsp-id = <0x0>;
		};

		qcom,msm-pcm-routing {
			compatible = "qcom,msm-pcm-routing";
		};

		qcom,msm-compr-dsp {
			compatible = "qcom,msm-compr-dsp";
		};

		qcom,msm-voip-dsp {
			compatible = "qcom,msm-voip-dsp";
		};

		qcom,msm-pcm-voice {
			compatible = "qcom,msm-pcm-voice";
		};

		qcom,msm-stub-codec {
			compatible = "qcom,msm-stub-codec";
		};

		qcom,msm-dai-fe {
			compatible = "qcom,msm-dai-fe";
		};

		qcom,msm-pcm-afe {
			compatible = "qcom,msm-pcm-afe";
		};

		qcom,msm-pcm-hostless {
			compatible = "qcom,msm-pcm-hostless";
		};

		qcom,msm-voice-host-pcm {
			compatible = "qcom,msm-voice-host-pcm";
		};

		qcom,msm-pcm-loopback {
			compatible = "qcom,msm-pcm-loopback";
		};

		qcom,msm-dai-stub {
			compatible = "qcom,msm-dai-stub";

			qcom,msm-dai-stub-dtmf-tx {
				compatible = "qcom,msm-dai-stub-dev";
				qcom,msm-dai-stub-dev-id = <0x4>;
			};

			qcom,msm-dai-stub-host-rx-capture-tx {
				compatible = "qcom,msm-dai-stub-dev";
				qcom,msm-dai-stub-dev-id = <0x5>;
			};

			qcom,msm-dai-stub-host-rx-playback-rx {
				compatible = "qcom,msm-dai-stub-dev";
				qcom,msm-dai-stub-dev-id = <0x6>;
			};

			qcom,msm-dai-stub-host-tx-capture-tx {
				compatible = "qcom,msm-dai-stub-dev";
				qcom,msm-dai-stub-dev-id = <0x7>;
			};

			qcom,msm-dai-stub-host-tx-playback-rx {
				compatible = "qcom,msm-dai-stub-dev";
				qcom,msm-dai-stub-dev-id = <0x8>;
			};
		};

		qcom,msm-dai-q6 {
			compatible = "qcom,msm-dai-q6";

			qcom,msm-dai-q6-be-afe-pcm-rx {
				compatible = "qcom,msm-dai-q6-dev";
				qcom,msm-dai-q6-dev-id = <0xe0>;
			};

			qcom,msm-dai-q6-be-afe-pcm-tx {
				compatible = "qcom,msm-dai-q6-dev";
				qcom,msm-dai-q6-dev-id = <0xe1>;
			};

			qcom,msm-dai-q6-afe-proxy-rx {
				compatible = "qcom,msm-dai-q6-dev";
				qcom,msm-dai-q6-dev-id = <0xf1>;
			};

			qcom,msm-dai-q6-afe-proxy-tx {
				compatible = "qcom,msm-dai-q6-dev";
				qcom,msm-dai-q6-dev-id = <0xf0>;
			};

			qcom,msm-dai-q6-incall-record-rx {
				compatible = "qcom,msm-dai-q6-dev";
				qcom,msm-dai-q6-dev-id = <0x8003>;
			};

			qcom,msm-dai-q6-incall-record-tx {
				compatible = "qcom,msm-dai-q6-dev";
				qcom,msm-dai-q6-dev-id = <0x8004>;
			};

			qcom,msm-dai-q6-incall-music-rx {
				compatible = "qcom,msm-dai-q6-dev";
				qcom,msm-dai-q6-dev-id = <0x8005>;
			};
		};

		qcom,msm-pcm-dtmf {
			compatible = "qcom,msm-pcm-dtmf";
		};

		qcom,msm-pri-auxpcm {
			compatible = "qcom,msm-auxpcm-dev";
			qcom,msm-cpudai-auxpcm-mode = <0x0 0x0>;
			qcom,msm-cpudai-auxpcm-sync = <0x1 0x1>;
			qcom,msm-cpudai-auxpcm-frame = <0x5 0x4>;
			qcom,msm-cpudai-auxpcm-quant = <0x2 0x2>;
			qcom,msm-cpudai-auxpcm-num-slots = <0x1 0x1>;
			qcom,msm-cpudai-auxpcm-slot-mapping = <0x1 0x1>;
			qcom,msm-cpudai-auxpcm-data = <0x0 0x0>;
			qcom,msm-cpudai-auxpcm-pcm-clk-rate = <0x1f4000 0x1f4000>;
			qcom,msm-auxpcm-interface = "primary";
		};

		qcom,msm-dai-mi2s {
			compatible = "qcom,msm-dai-mi2s";

			qcom,msm-dai-q6-mi2s-prim {
				compatible = "qcom,msm-dai-q6-mi2s";
				qcom,msm-dai-q6-mi2s-dev-id = <0x0>;
				qcom,msm-mi2s-rx-lines = <0x2>;
				qcom,msm-mi2s-tx-lines = <0x1>;
			};
		};

		qcom,cnss@7000000 {
			compatible = "qcom,cnss";
			wlan-en-gpio = <0x11 0x46 0x0>;
			vdd-wlan-supply = <0x3b>;
			reg = <0x7000000 0x100000>;
			reg-names = "ramdump";
			qcom,notify-modem-status;
		};

		regulator-isl80101 {
			compatible = "regulator-fixed";
			regulator-name = "sd_2.95";
			gpio = <0x11 0x59 0x0>;
			startup-delay-us = <0x3e8>;
			enable-active-high;
			linux,phandle = <0x2c>;
			phandle = <0x2c>;
		};

		spi_eth_phy_vreg {
			compatible = "regulator-fixed";
			regulator-name = "ethernet_phy";
			regulator-always-on;
		};

		wlan_vreg {
			compatible = "regulator-fixed";
			regulator-name = "wlan_vreg";
			regulator-always-on;
			status = "ok";
			linux,phandle = <0x3b>;
			phandle = <0x3b>;
		};

		qcom,pmd9635-battery {
			compatible = "qcom,pmd9635-battery";
			pmd9635-battery,vbat-channel = <0x15>;
			pmd9635-battery,tbat-channel = <0x11>;
		};
	};

	qcom,gpio_keys_button {
		compatible = "gpio-keys";
		input-name = "gpio-keys";

		button_wps@20 {
			label = "WPS Button";
			linux,code = <0x211>;
			linux,input-type = <0x1>;
			gpios = <0x11 0x14 0x1>;
			debounce-interval = <0xf>;
		};
	};
};
